VERSION "dbc-export 1 2025.20.8"

NS_ :

BS_:

BU_: ADSP APB APP APS APSB BB BMS CC CMP CMPD CP DAS DI DIF DIR DPB EPAS3P EPAS3S EPASTP EPASTS EPBL EPBR ESP EVSE FC GTW HCML HCMR HVP IBST ICR IDB LS OCS1P ODIN PARK PCS PLG PM PMF PMR PNCD PTC RADC RCM RCM2 RCM3 RCU SCCM SCM SCS SDCR TAS TCU TPMS TRCM UDS UI UIS UMC USM VC VCFRONT VCLEFT VCRIGHT VCSEC VEH

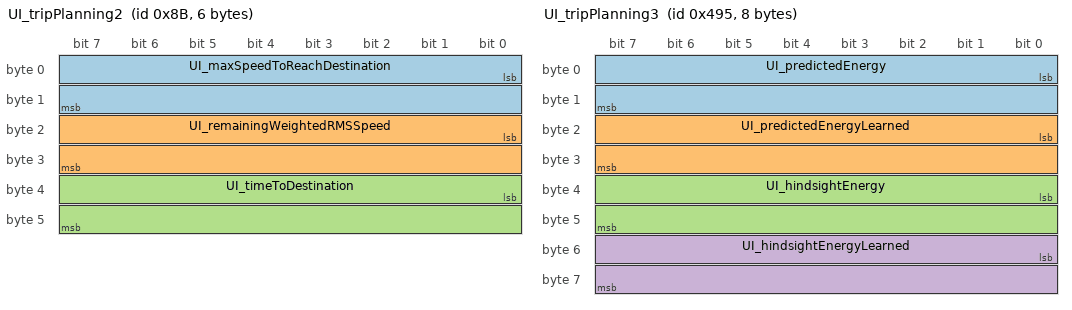
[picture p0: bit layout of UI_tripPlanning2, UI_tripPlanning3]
BO_ 139 UI_tripPlanning2: 6 UI
 SG_ UI_maxSpeedToReachDestination : 0|16@1+ (0.01,0) [0|655.34] "m/s" Vector__XXX
 SG_ UI_remainingWeightedRMSSpeed : 16|16@1+ (0.01,0) [0|655.34] "m/s" Vector__XXX
 SG_ UI_timeToDestination : 32|16@1+ (1,0) [0|65534] "s" Vector__XXX

BO_ 1173 UI_tripPlanning3: 8 UI
 SG_ UI_predictedEnergy : 0|16@1- (0.01,0) [-327.67|327.67] "kWh" Vector__XXX
 SG_ UI_predictedEnergyLearned : 16|16@1- (0.01,0) [-327.68|327.67] "kWh" Vector__XXX
 SG_ UI_hindsightEnergy : 32|16@1- (0.01,0) [-327.67|327.67] "kWh" Vector__XXX
 SG_ UI_hindsightEnergyLearned : 48|16@1- (0.01,0) [-327.68|327.67] "kWh" Vector__XXX

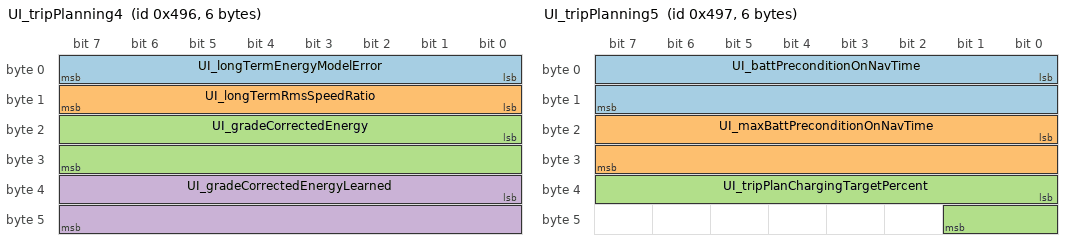
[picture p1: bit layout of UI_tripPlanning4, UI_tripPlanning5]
BO_ 1174 UI_tripPlanning4: 6 UI
 SG_ UI_longTermEnergyModelError : 0|8@1- (0.5,0) [-64|63.5] "whpm" Vector__XXX
 SG_ UI_longTermRmsSpeedRatio : 8|8@1+ (0.01,0) [0|2.54] "1" Vector__XXX
 SG_ UI_gradeCorrectedEnergy : 16|16@1- (0.01,0) [-327.68|327.67] "kWh" Vector__XXX
 SG_ UI_gradeCorrectedEnergyLearned : 32|16@1- (0.01,0) [-327.68|327.67] "kWh" Vector__XXX

BO_ 1175 UI_tripPlanning5: 6 UI
 SG_ UI_battPreconditionOnNavTime : 0|16@1+ (1,0) [0|65534] "s" Vector__XXX
 SG_ UI_maxBattPreconditionOnNavTime : 16|16@1+ (1,0) [0|65534] "s" Vector__XXX
 SG_ UI_tripPlanChargingTargetPercent : 32|10@1+ (0.1,0) [0|102.2] "%" Vector__XXX

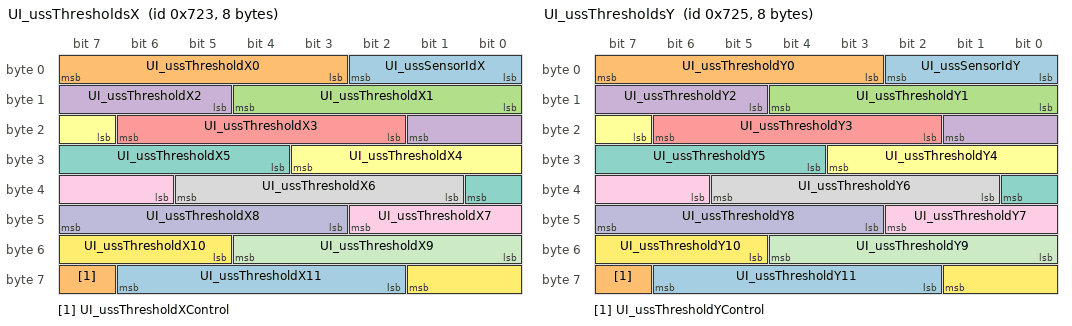
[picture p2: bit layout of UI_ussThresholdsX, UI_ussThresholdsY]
BO_ 1827 UI_ussThresholdsX: 8 UI
 SG_ UI_ussSensorIdX : 0|3@1+ (1,0) [0|7] "" Vector__XXX
 SG_ UI_ussThresholdX0 : 3|5@1+ (1,0) [0|31] "" Vector__XXX
 SG_ UI_ussThresholdX1 : 8|5@1+ (1,0) [0|31] "" Vector__XXX
 SG_ UI_ussThresholdX2 : 13|5@1+ (1,0) [0|31] "" Vector__XXX
 SG_ UI_ussThresholdX3 : 18|5@1+ (1,0) [0|31] "" Vector__XXX
 SG_ UI_ussThresholdX4 : 23|5@1+ (1,0) [0|31] "" Vector__XXX
 SG_ UI_ussThresholdX5 : 28|5@1+ (1,0) [0|31] "" Vector__XXX
 SG_ UI_ussThresholdX6 : 33|5@1+ (1,0) [0|31] "" Vector__XXX
 SG_ UI_ussThresholdX7 : 38|5@1+ (1,0) [0|31] "" Vector__XXX
 SG_ UI_ussThresholdX8 : 43|5@1+ (1,0) [0|31] "" Vector__XXX
 SG_ UI_ussThresholdX9 : 48|5@1+ (1,0) [0|31] "" Vector__XXX
 SG_ UI_ussThresholdX10 : 53|5@1+ (1,0) [0|31] "" Vector__XXX
 SG_ UI_ussThresholdX11 : 58|5@1+ (1,0) [0|31] "" Vector__XXX
 SG_ UI_ussThresholdXControl : 63|1@1+ (1,0) [0|1] "" Vector__XXX

BO_ 1829 UI_ussThresholdsY: 8 UI
 SG_ UI_ussSensorIdY : 0|3@1+ (1,0) [0|7] "" Vector__XXX
 SG_ UI_ussThresholdY0 : 3|5@1+ (1,0) [0|31] "" Vector__XXX
 SG_ UI_ussThresholdY1 : 8|5@1+ (1,0) [0|31] "" Vector__XXX
 SG_ UI_ussThresholdY2 : 13|5@1+ (1,0) [0|31] "" Vector__XXX
 SG_ UI_ussThresholdY3 : 18|5@1+ (1,0) [0|31] "" Vector__XXX
 SG_ UI_ussThresholdY4 : 23|5@1+ (1,0) [0|31] "" Vector__XXX
 SG_ UI_ussThresholdY5 : 28|5@1+ (1,0) [0|31] "" Vector__XXX
 SG_ UI_ussThresholdY6 : 33|5@1+ (1,0) [0|31] "" Vector__XXX
 SG_ UI_ussThresholdY7 : 38|5@1+ (1,0) [0|31] "" Vector__XXX
 SG_ UI_ussThresholdY8 : 43|5@1+ (1,0) [0|31] "" Vector__XXX
 SG_ UI_ussThresholdY9 : 48|5@1+ (1,0) [0|31] "" Vector__XXX
 SG_ UI_ussThresholdY10 : 53|5@1+ (1,0) [0|31] "" Vector__XXX
 SG_ UI_ussThresholdY11 : 58|5@1+ (1,0) [0|31] "" Vector__XXX
 SG_ UI_ussThresholdYControl : 63|1@1+ (1,0) [0|1] "" Vector__XXX

BO_ 627 UI_vehicleControl: 8 UI
 SG_ UI_powerStateRequest : 0|2@1+ (1,0) [0|3] "" Vector__XXX
 SG_ UI_childDoorLockOnRight : 2|1@1+ (1,0) [0|1] "" Vector__XXX
 SG_ UI_frontFogSwitch : 3|1@1+ (1,0) [0|1] "" Vector__XXX
 SG_ UI_summonActive : 4|1@1+ (1,0) [0|1] "" Vector__XXX
 SG_ UI_frunkRequest : 5|1@1+ (1,0) [0|1] "" Vector__XXX
 SG_ UI_wiperMode : 6|2@1+ (1,0) [1|3] "" Vector__XXX
 SG_ UI_steeringBacklightEnabled : 8|1@1+ (1,0) [0|1] "" Vector__XXX
 SG_ UI_steeringButtonMode : 9|3@1+ (1,0) [0|7] "" Vector__XXX
 SG_ UI_walkUpUnlock : 12|1@1+ (1,0) [0|1] "" Vector__XXX
 SG_ UI_walkAwayLock : 13|1@1+ (1,0) [0|1] "" Vector__XXX
 SG_ UI_unlockOnPark : 14|1@1+ (1,0) [0|1] "" Vector__XXX
 SG_ UI_globalUnlockOn : 15|1@1+ (1,0) [0|1] "" Vector__XXX
 SG_ UI_childDoorLockOnLeft : 16|1@1+ (1,0) [0|1] "" Vector__XXX
 SG_ UI_lockRequest : 17|3@1+ (1,0) [0|6] "" Vector__XXX
 SG_ UI_alarmEnabled : 20|1@1+ (1,0) [0|1] "" Vector__XXX
 SG_ UI_intrusionSensorOn : 21|1@1+ (1,0) [0|1] "" Vector__XXX
 SG_ UI_stop12vSupport : 22|1@1+ (1,0) [0|1] "" Vector__XXX
 SG_ UI_rearFogSwitch : 23|1@1+ (1,0) [0|1] "" Vector__XXX
 SG_ UI_mirrorFoldRequest : 24|2@1+ (1,0) [0|2] "" Vector__XXX
 SG_ UI_mirrorHeatRequest : 26|1@1+ (1,0) [0|1] "" Vector__XXX
 SG_ UI_remoteStartRequest : 27|3@1+ (1,0) [0|7] "" Vector__XXX
 SG_ UI_seeYouHomeLightingOn : 30|1@1+ (1,0) [0|1] "" Vector__XXX
 SG_ UI_powerOff : 31|1@1+ (1,0) [0|1] "" Vector__XXX
 SG_ UI_displayBrightnessLevel : 32|8@1+ (0.5,0) [0|127] "%" Vector__XXX
 SG_ UI_ambientLightingEnabled : 40|1@1+ (1,0) [0|1] "" Vector__XXX
 SG_ UI_autoHighBeamEnabled : 41|1@1+ (1,0) [0|1] "" Vector__XXX
 SG_ UI_frontLeftSeatHeatReq : 42|2@1+ (1,0) [0|3] "" Vector__XXX
 SG_ UI_frontRightSeatHeatReq : 44|2@1+ (1,0) [0|3] "" Vector__XXX
 SG_ UI_rearLeftSeatHeatReq : 46|2@1+ (1,0) [0|3] "" Vector__XXX
 SG_ UI_rearCenterSeatHeatReq : 48|2@1+ (1,0) [0|3] "" Vector__XXX
 SG_ UI_rearRightSeatHeatReq : 50|2@1+ (1,0) [0|3] "" Vector__XXX
 SG_ UI_autoFoldMirrorsOn : 52|1@1+ (1,0) [0|1] "" Vector__XXX
 SG_ UI_mirrorDipOnReverse : 53|1@1+ (1,0) [0|1] "" Vector__XXX
 SG_ UI_remoteClosureRequest : 54|2@1+ (1,0) [0|2] "" Vector__XXX
 SG_ UI_wiperRequest : 56|3@1+ (1,0) [1|7] "" Vector__XXX
 SG_ UI_domeLightSwitch : 59|2@1+ (1,0) [0|3] "" Vector__XXX
 SG_ UI_honkHorn : 61|1@1+ (1,0) [0|1] "" Vector__XXX
 SG_ UI_driveStateRequest : 62|1@1+ (1,0) [0|1] "" Vector__XXX
 SG_ UI_rearWindowLockout : 63|1@1+ (1,0) [0|1] "" Vector__XXX

BO_ 947 UI_vehicleControl2: 8 UI
 SG_ UI_gloveboxRequest : 0|1@1+ (1,0) [0|1] "" Vector__XXX
 SG_ UI_trunkRequest : 1|1@1+ (1,0) [0|1] "" Vector__XXX
 SG_ UI_UMCUpdateInhibit : 2|1@1+ (1,0) [0|1] "" Vector__XXX
 SG_ UI_WCUpdateInhibit : 3|1@1+ (1,0) [0|1] "" Vector__XXX
 SG_ UI_soundHornOnLock : 4|1@1+ (1,0) [0|1] "" Vector__XXX
 SG_ UI_locksPanelActive : 5|1@1+ (1,0) [0|1] "" Vector__XXX
 SG_ UI_PINToDriveEnabled : 6|1@1+ (1,0) [0|1] "" Vector__XXX
 SG_ UI_PINToDrivePassed : 7|1@1+ (1,0) [0|1] "" Vector__XXX
 SG_ UI_disableMirrorAutoDim : 8|1@1+ (1,0) [0|1] "" Vector__XXX
 SG_ UI_lightSwitch : 9|3@1+ (1,0) [0|7] "" Vector__XXX
 SG_ UI_readyToAddKey : 12|1@1+ (1,0) [0|1] "" Vector__XXX
 SG_ UI_alarmTriggerRequest : 13|1@1+ (1,0) [0|1] "" Vector__XXX
 SG_ UI_VCSECFeature1 : 14|1@1+ (1,0) [0|1] "" Vector__XXX
 SG_ UI_VCLEFTFeature1 : 15|1@1+ (1,0) [0|1] "" Vector__XXX
 SG_ UI_summonState : 16|2@1+ (1,0) [1|3] "" Vector__XXX
 SG_ UI_displayOnForUser : 18|1@1+ (1,0) [0|1] "" Vector__XXX
 SG_ UI_freeRollModeRequest : 19|1@1+ (1,0) [0|1] "" Vector__XXX
 SG_ UI_BLEPushNotificationRequest : 20|1@1+ (1,0) [0|1] "" Vector__XXX
 SG_ UI_pairKeyQRCodeDisplaying : 21|1@1+ (1,0) [0|1] "" Vector__XXX
 SG_ UI_keepAutopilotAwake : 22|1@1+ (1,0) [0|1] "" Vector__XXX
 SG_ UI_batteryPreconditioningRequest : 23|1@1+ (1,0) [0|1] "" Vector__XXX
 SG_ UI_coastDownMode : 24|1@1+ (1,0) [0|1] "" Vector__XXX
 SG_ UI_autopilotPowerStateRequest : 25|2@1+ (1,0) [0|3] "" Vector__XXX
 SG_ UI_shorted12VCellTestMode : 27|2@1+ (1,0) [0|3] "" Vector__XXX
 SG_ UI_autoRollWindowsOnLockEnable : 29|1@1+ (1,0) [0|1] "" Vector__XXX
 SG_ UI_virtualPitchSensorOverrideOKF : 30|1@1+ (1,0) [0|1] "" Vector__XXX
 SG_ UI_conditionalLoggingEnabledVCSE : 31|1@1+ (1,0) [0|1] "" Vector__XXX
 SG_ UI_WC3UpdateInhibit : 32|1@1+ (1,0) [0|1] "" Vector__XXX
 SG_ UI_steeringWheelHeatReq : 33|1@1+ (1,0) [0|1] "" Vector__XXX
 SG_ UI_disableHorn : 34|1@1+ (1,0) [0|1] "" Vector__XXX
 SG_ UI_frontLeftSeatFanReq : 37|2@1+ (1,0) [0|3] "" Vector__XXX
 SG_ UI_frontRightSeatAutoClimateReq : 39|1@1+ (1,0) [0|1] "" Vector__XXX
 SG_ UI_frontRightSeatFanReq : 40|2@1+ (1,0) [0|3] "" Vector__XXX
 SG_ UI_sleepFeature1 : 51|1@1+ (1,0) [0|1] "" Vector__XXX
 SG_ UI_dcr12VThreshold : 52|4@1+ (1,0) [0|15] "" Vector__XXX
 SG_ UI_frontLeftSeatAutoClimateReq : 56|1@1+ (1,0) [0|1] "" Vector__XXX
 SG_ UI_wiperHeaterReq : 57|1@1+ (1,0) [0|1] "" Vector__XXX
 SG_ UI_tireSeason : 59|1@1+ (1,0) [0|1] "" Vector__XXX
 SG_ UI_saveTireConfigReq : 60|1@1+ (1,0) [0|1] "" Vector__XXX
 SG_ UI_silentAlarm : 61|1@1+ (1,0) [0|1] "" Vector__XXX
 SG_ UI_sleepFeature2 : 63|1@1+ (1,0) [0|1] "" Vector__XXX

BO_ 628 UI_vehicleControl3: 8 UI
 SG_ UI_lightFlashRequest : 0|2@1+ (1,0) [0|3] "" Vector__XXX
 SG_ UI_keylessDrivingEnabled : 2|1@1+ (1,0) [0|1] "" Vector__XXX
 SG_ UI_phoneCallActive : 3|1@1+ (1,0) [0|1] "" Vector__XXX
 SG_ UI_drivingSideVEH : 4|2@1+ (1,0) [0|3] "" Vector__XXX
 SG_ UI_keyPairResponse : 6|2@1+ (1,0) [0|3] "" Vector__XXX
 SG_ UI_lightShowClosuresEnabled : 8|1@1+ (1,0) [0|1] "" Vector__XXX
 SG_ UI_steeringWheelHeatAutoReq : 9|1@1+ (1,0) [0|1] "" Vector__XXX
 SG_ UI_steeringWheelHeatLevelReq : 10|2@1+ (1,0) [0|3] "" Vector__XXX
 SG_ UI_headlightPulseRequest : 12|1@1+ (1,0) [0|1] "" Vector__XXX
 SG_ UI_VCSECFeature2 : 13|1@1+ (1,0) [0|1] "" Vector__XXX
 SG_ UI_VCSECFeature3 : 14|1@1+ (1,0) [0|1] "" Vector__XXX
 SG_ UI_VCSECFeature4 : 15|1@1+ (1,0) [0|1] "" Vector__XXX
 SG_ UI_VCSECFeature5 : 16|1@1+ (1,0) [0|1] "" Vector__XXX
 SG_ UI_shortHornRequest : 17|1@1+ (1,0) [0|1] "" Vector__XXX
 SG_ UI_packTempLoggingRequest : 18|1@1+ (1,0) [0|1] "" Vector__XXX
 SG_ UI_UMC3UpdateInhibit : 22|1@1+ (1,0) [0|1] "" Vector__XXX
 SG_ UI_handsFreeTrunk : 23|1@1+ (1,0) [0|1] "" Vector__XXX
 SG_ UI_displayRedShiftActive : 24|1@1+ (1,0) [0|1] "" Vector__XXX
 SG_ UI_handsFreeFrunk : 25|1@1+ (1,0) [0|1] "" Vector__XXX
 SG_ UI_fasciaCameraWashRequest : 26|1@1+ (1,0) [0|1] "" Vector__XXX
 SG_ UI_autoClosuresExcludeHome : 27|1@1+ (1,0) [0|1] "" Vector__XXX
 SG_ UI_leftRearSeatAdjustmentRequest : 28|3@1+ (1,0) [0|7] "" Vector__XXX
 SG_ UI_rightRearSeatAdjustmentReques : 32|3@1+ (1,0) [0|7] "" Vector__XXX
 SG_ UI_blindSpotIndicatorLightReques : 35|1@1+ (1,0) [0|1] "" Vector__XXX
 SG_ UI_etcBluetoothControl : 36|2@1+ (1,0) [0|3] "" Vector__XXX
 SG_ UI_keepOnAccessoryPortsReq : 38|1@1+ (1,0) [0|1] "" Vector__XXX
 SG_ UI_fasciaCameraShown : 39|1@1+ (1,0) [0|1] "" Vector__XXX
 SG_ UI_rearSeatChildLock : 40|2@1+ (1,0) [0|3] "" Vector__XXX
 SG_ UI_windowPercentageRequest : 42|6@1- (5,0) [-100|100] "%" Vector__XXX
 SG_ UI_windowRequestedFL : 48|1@1+ (1,0) [0|1] "" Vector__XXX
 SG_ UI_windowRequestedFR : 49|1@1+ (1,0) [0|1] "" Vector__XXX
 SG_ UI_windowRequestedRL : 50|1@1+ (1,0) [0|1] "" Vector__XXX
 SG_ UI_windowRequestedRR : 51|1@1+ (1,0) [0|1] "" Vector__XXX
 SG_ UI_windowRequest : 52|3@1+ (1,0) [0|7] "" Vector__XXX
 SG_ UI_closeTrunkRequest : 55|1@1+ (1,0) [0|1] "" Vector__XXX
 SG_ UI_childPresenceDetectionDisable : 56|1@1+ (1,0) [0|1] "" Vector__XXX
 SG_ UI_derivedLoadshedFeature : 59|1@1+ (1,0) [0|1] "" Vector__XXX
 SG_ UI_rearSeatFoldConfirmed : 60|1@1+ (1,0) [0|1] "" Vector__XXX
 SG_ UI_leftRearSeatRequestFromRearDi : 61|1@1+ (1,0) [0|1] "" Vector__XXX
 SG_ UI_selfParkStandingBy : 62|1@1+ (1,0) [0|1] "" Vector__XXX
 SG_ UI_rightRearSeatRequestFromRearD : 63|1@1+ (1,0) [0|1] "" Vector__XXX

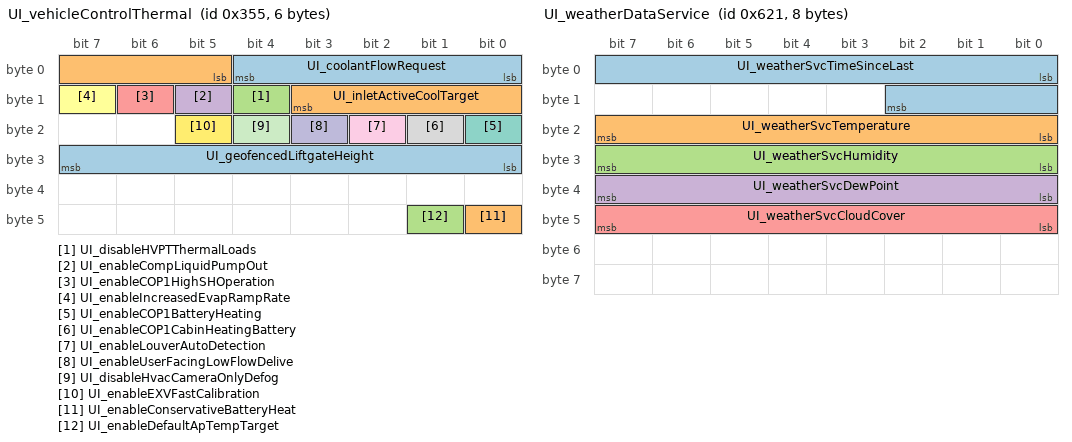
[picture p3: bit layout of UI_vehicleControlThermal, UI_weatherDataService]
BO_ 853 UI_vehicleControlThermal: 6 UI
 SG_ UI_coolantFlowRequest : 0|5@1+ (1,0) [0|25] "LPM" Vector__XXX
 SG_ UI_inletActiveCoolTarget : 5|7@1+ (1,0) [0|127] "degC" Vector__XXX
 SG_ UI_disableHVPTThermalLoads : 12|1@1+ (1,0) [0|1] "" Vector__XXX
 SG_ UI_enableCompLiquidPumpOut : 13|1@1+ (1,0) [0|1] "" Vector__XXX
 SG_ UI_enableCOP1HighSHOperation : 14|1@1+ (1,0) [0|1] "" Vector__XXX
 SG_ UI_enableIncreasedEvapRampRate : 15|1@1+ (1,0) [0|1] "" Vector__XXX
 SG_ UI_enableCOP1BatteryHeating : 16|1@1+ (1,0) [0|1] "" Vector__XXX
 SG_ UI_enableCOP1CabinHeatingBattery : 17|1@1+ (1,0) [0|1] "" Vector__XXX
 SG_ UI_enableLouverAutoDetection : 18|1@1+ (1,0) [0|1] "" Vector__XXX
 SG_ UI_enableUserFacingLowFlowDelive : 19|1@1+ (1,0) [0|1] "" Vector__XXX
 SG_ UI_disableHvacCameraOnlyDefog : 20|1@1+ (1,0) [0|1] "" Vector__XXX
 SG_ UI_enableEXVFastCalibration : 21|1@1+ (1,0) [0|1] "" Vector__XXX
 SG_ UI_geofencedLiftgateHeight : 24|8@1+ (1,0) [0|254] "cm" Vector__XXX
 SG_ UI_enableConservativeBatteryHeat : 40|1@1+ (1,0) [0|1] "" Vector__XXX
 SG_ UI_enableDefaultApTempTarget : 41|1@1+ (1,0) [0|1] "" Vector__XXX

BO_ 644 UI_vehicleModes: 8 UI
 SG_ UI_factoryMode : 0|1@1+ (1,0) [0|1] "" Vector__XXX
 SG_ UI_transportMode : 1|1@1+ (1,0) [0|1] "" Vector__XXX
 SG_ UI_showroomMode : 2|1@1+ (1,0) [0|1] "" Vector__XXX
 SG_ UI_serviceMode : 3|1@1+ (1,0) [0|1] "" Vector__XXX
 SG_ UI_isDelivered : 4|1@1+ (1,0) [0|1] "" Vector__XXX
 SG_ UI_hasEverBeenDelivered : 5|1@1+ (1,0) [0|1] "" Vector__XXX
 SG_ UI_homelinkV2Command0 : 8|8@1+ (1,0) [0|255] "" Vector__XXX
 SG_ UI_homelinkV2Command1 : 16|8@1+ (1,0) [0|255] "" Vector__XXX
 SG_ UI_homelinkV2Command2 : 24|8@1+ (1,0) [0|255] "" Vector__XXX
 SG_ UI_carWashMode : 32|1@1+ (1,0) [0|1] "" Vector__XXX
 SG_ UI_valetMode : 33|1@1+ (1,0) [0|1] "" Vector__XXX
 SG_ UI_gameMode : 34|1@1+ (1,0) [0|1] "" Vector__XXX
 SG_ UI_diagnosticsAllowed : 35|1@1+ (1,0) [0|1] "" Vector__XXX
 SG_ UI_serviceModePlus : 36|1@1+ (1,0) [0|1] "" Vector__XXX
 SG_ UI_premiumAmpPowerOff : 37|1@1+ (1,0) [0|1] "" Vector__XXX
 SG_ UI_signedCmdHardLocked : 38|1@1+ (1,0) [0|1] "" Vector__XXX
 SG_ UI_signedCmdServiceMode : 39|1@1+ (1,0) [0|1] "" Vector__XXX
 SG_ UI_closureEasterEggStatus : 40|2@1+ (1,0) [0|3] "" Vector__XXX
 SG_ UI_lightShowType : 42|3@1+ (1,0) [0|7] "" Vector__XXX
 SG_ UI_sohTestRequest : 45|1@1+ (1,0) [0|1] "" Vector__XXX
 SG_ UI_vehicleModesCounter : 52|4@1+ (1,0) [0|15] "" Vector__XXX
 SG_ UI_vehicleModesChecksum : 56|8@1+ (1,0) [0|255] "" Vector__XXX

BO_ 595 UI_ventPanelControlRequest: 8 UI
 SG_ UI_ventPanelControlRequestIndex M : 0|1@1+ (1,0) [0|1] "" Vector__XXX
 SG_ UI_ventPanelLeftPositionX m0 : 8|8@1+ (0.5,0) [0|100] "%" Vector__XXX
 SG_ UI_ventPanelLeftPositionY m0 : 16|8@1+ (0.5,0) [0|100] "%" Vector__XXX
 SG_ UI_ventPanelLeftLateralSplit m0 : 24|8@1+ (0.5,0) [0|100] "%" Vector__XXX
 SG_ UI_ventPanelRightPositionX m0 : 32|8@1+ (0.5,0) [0|100] "%" Vector__XXX
 SG_ UI_ventPanelRightPositionY m0 : 40|8@1+ (0.5,0) [0|100] "%" Vector__XXX
 SG_ UI_ventPanelRightLateralSplit m0 : 48|8@1+ (0.5,0) [0|100] "%" Vector__XXX
 SG_ UI_ventPanelLeftLateralMode m0 : 56|2@1+ (1,0) [0|3] "" Vector__XXX
 SG_ UI_ventPanelRightLateralMode m0 : 58|2@1+ (1,0) [0|3] "" Vector__XXX
 SG_ UI_hvacReqActiveVents m0 : 60|2@1+ (1,0) [0|3] "" Vector__XXX
 SG_ UI_vent2RLeftPositionX m1 : 8|8@1+ (0.5,0) [0|100] "%" Vector__XXX
 SG_ UI_vent2RLeftPositionY m1 : 16|8@1+ (0.5,0) [0|100] "%" Vector__XXX
 SG_ UI_vent2RRightPositionX m1 : 24|8@1+ (0.5,0) [0|100] "%" Vector__XXX
 SG_ UI_vent2RRightPositionY m1 : 32|8@1+ (0.5,0) [0|100] "%" Vector__XXX

BO_ 1569 UI_weatherDataService: 8 UI
 SG_ UI_weatherSvcTimeSinceLast : 0|11@1+ (1,0) [0|2046] "minutes" Vector__XXX
 SG_ UI_weatherSvcTemperature : 16|8@1- (0.5,0) [-64|63] "degC" Vector__XXX
 SG_ UI_weatherSvcHumidity : 24|8@1+ (0.5,0) [0|127] "%" Vector__XXX
 SG_ UI_weatherSvcDewPoint : 32|8@1+ (0.5,0) [0|127] "degC" Vector__XXX
 SG_ UI_weatherSvcCloudCover : 40|8@1+ (0.5,0) [0|127] "%" Vector__XXX

BO_ 1533 UMC_alertLog: 8 UMC
 SG_ UMC_alertID M : 0|15@1+ (1,0) [0|32767] "" Vector__XXX
 SG_ UMC_alertType : 15|1@1+ (1,0) [0|1] "" Vector__XXX
 SG_ UMC_a001_groundImpedance m1 : 32|32@1+ (1,0) [0|4294967295] "Ohm" Vector__XXX
 SG_ UMC_a002_ccidRmsCurrent m2 : 16|12@1+ (0.001,0) [0|4.095] "A" Vector__XXX
 SG_ UMC_a002_ccidRmsCurrentAvg m2 : 28|12@1+ (0.001,0) [0|4.095] "A" Vector__XXX
 SG_ UMC_a002_ccidFaultReason m2 : 50|4@1+ (1,0) [1|15] "" Vector__XXX
 SG_ UMC_a002_ccidFaultBucket m2 : 54|4@1+ (1,0) [0|15] "" Vector__XXX
 SG_ UMC_a003_faultType m3 : 16|8@1+ (1,0) [0|255] "" Vector__XXX
 SG_ UMC_a003_ccidSelfTestDuty m3 : 24|16@1+ (0.0001,50) [50|56.5535] "A" Vector__XXX
 SG_ UMC_a003_ccidSelfTestCurrent m3 : 40|16@1+ (0.0001,0) [0|6.5535] "A" Vector__XXX
 SG_ UMC_a004_lineVoltage m4 : 16|16@1+ (1,0) [0|65535] "Vrms" Vector__XXX
 SG_ UMC_a004_inputVoltage m4 : 32|16@1+ (0.01,0) [0|655.35] "V" Vector__XXX
 SG_ UMC_a004_inputNeutralVoltage m4 : 48|16@1+ (0.01,0) [0|655.35] "V" Vector__XXX
 SG_ UMC_a005_lineVoltage m5 : 16|16@1+ (1,0) [0|65535] "Vrms" Vector__XXX
 SG_ UMC_a005_inputVoltage m5 : 32|16@1+ (0.01,0) [0|655.35] "V" Vector__XXX
 SG_ UMC_a005_inputNeutralVoltage m5 : 48|16@1+ (0.01,0) [0|655.35] "V" Vector__XXX
 SG_ UMC_a006_outputVoltage m6 : 16|16@1+ (1,0) [0|65535] "Vrms" Vector__XXX
 SG_ UMC_a006_faultType m6 : 32|4@1+ (1,0) [0|15] "" Vector__XXX
 SG_ UMC_a006_umcReceptacleVoltage m6 : 36|12@1+ (0.1,0) [0|409.5] "V" Vector__XXX
 SG_ UMC_a006_handleVoltage m6 : 48|12@1+ (0.1,0) [0|409.5] "V" Vector__XXX
 SG_ UMC_a006_line1StuckClosed m6 : 60|1@1+ (1,0) [0|1] "" Vector__XXX
 SG_ UMC_a006_line2StuckClosed m6 : 61|1@1+ (1,0) [0|1] "" Vector__XXX
 SG_ UMC_a007_pcbaTemp m7 : 16|16@1+ (1,0) [0|65535] "degC" Vector__XXX
 SG_ UMC_a008_wallPlugTemp m8 : 16|16@1+ (1,0) [0|65535] "degC" Vector__XXX
 SG_ UMC_a008_SA_region m8 : 32|4@1+ (1,0) [0|15] "" Vector__XXX
 SG_ UMC_a008_SA_current m8 : 40|8@1+ (1,0) [0|255] "A" Vector__XXX
 SG_ UMC_a009_vehConnTemp m9 : 16|16@1+ (1,0) [0|65535] "degC" Vector__XXX
 SG_ UMC_a010_inputTerminalsTemp m10 : 16|16@1+ (1,0) [0|65535] "degC" Vector__XXX
 SG_ UMC_a012_pilotHigh m12 : 16|12@1- (0.01,0) [-20.48|20.47] "V" Vector__XXX
 SG_ UMC_a012_pilotLow m12 : 28|12@1- (0.01,0) [-20.48|20.47] "V" Vector__XXX
 SG_ UMC_a013_SA_region m13 : 16|4@1+ (1,0) [0|15] "" Vector__XXX
 SG_ UMC_a013_SA_current m13 : 24|8@1+ (1,0) [0|255] "A" Vector__XXX
 SG_ UMC_a015_SA_region m15 : 16|4@1+ (1,0) [0|15] "" Vector__XXX
 SG_ UMC_a015_SA_current m15 : 24|8@1+ (1,0) [0|255] "A" Vector__XXX
 SG_ UMC_a016_pcbaTemp m16 : 16|16@1+ (1,0) [0|65535] "degC" Vector__XXX
 SG_ UMC_a017_wallPlugTemp m17 : 16|16@1+ (1,0) [0|65535] "degC" Vector__XXX
 SG_ UMC_a017_SA_region m17 : 32|4@1+ (1,0) [0|15] "" Vector__XXX
 SG_ UMC_a017_SA_current m17 : 40|8@1+ (1,0) [0|255] "A" Vector__XXX
 SG_ UMC_a018_vehConnTemp m18 : 16|16@1+ (1,0) [0|65535] "degC" Vector__XXX
 SG_ UMC_a019_inputTerminalsTemp m19 : 16|16@1+ (1,0) [0|65535] "degC" Vector__XXX
 SG_ UMC_a024_groundImpedance m24 : 32|32@1+ (1,0) [0|4294967295] "Ohm" Vector__XXX
 SG_ UMC_a040_groundImpedance m40 : 32|32@1+ (1,0) [0|4294967295] "Ohm" Vector__XXX

BO_ 824 UMC_alertMatrix1: 8 UMC
 SG_ UMC_a001_gndMonIntrptLineSide : 0|1@1+ (1,0) [0|1] "" Vector__XXX
 SG_ UMC_a002_GFCITripped : 1|1@1+ (1,0) [0|1] "" Vector__XXX
 SG_ UMC_a003_GFCISelfTestFault : 2|1@1+ (1,0) [0|1] "" Vector__XXX
 SG_ UMC_a004_inputOverVoltage : 3|1@1+ (1,0) [0|1] "" Vector__XXX
 SG_ UMC_a005_inputUnderVoltage : 4|1@1+ (1,0) [0|1] "" Vector__XXX
 SG_ UMC_a006_contactorWelded : 5|1@1+ (1,0) [0|1] "" Vector__XXX
 SG_ UMC_a007_pcbaOT : 6|1@1+ (1,0) [0|1] "" Vector__XXX
 SG_ UMC_a008_wallPlugOT : 7|1@1+ (1,0) [0|1] "" Vector__XXX
 SG_ UMC_a009_vehConnOT : 8|1@1+ (1,0) [0|1] "" Vector__XXX
 SG_ UMC_a010_inputOT : 9|1@1+ (1,0) [0|1] "" Vector__XXX
 SG_ UMC_a011_proxDisconnected : 10|1@1+ (1,0) [0|1] "" Vector__XXX
 SG_ UMC_a012_pilotFault : 11|1@1+ (1,0) [0|1] "" Vector__XXX
 SG_ UMC_a013_SA_Temperature : 12|1@1+ (1,0) [0|1] "" Vector__XXX
 SG_ UMC_a014_SA_Genealogy : 13|1@1+ (1,0) [0|1] "" Vector__XXX
 SG_ UMC_a015_SA_Connection : 14|1@1+ (1,0) [0|1] "" Vector__XXX
 SG_ UMC_a016_pcbaOTFoldback : 15|1@1+ (1,0) [0|1] "" Vector__XXX
 SG_ UMC_a017_wallPlugOTFoldback : 16|1@1+ (1,0) [0|1] "" Vector__XXX
 SG_ UMC_a018_vehConnOTFoldback : 17|1@1+ (1,0) [0|1] "" Vector__XXX
 SG_ UMC_a019_inputOTFoldback : 18|1@1+ (1,0) [0|1] "" Vector__XXX
 SG_ UMC_a020_applicationCRC : 19|1@1+ (1,0) [0|1] "" Vector__XXX
 SG_ UMC_a021_dataBus : 20|1@1+ (1,0) [0|1] "" Vector__XXX
 SG_ UMC_a022_criticalRAM : 21|1@1+ (1,0) [0|1] "" Vector__XXX
 SG_ UMC_a023_adcSelfTest : 22|1@1+ (1,0) [0|1] "" Vector__XXX
 SG_ UMC_a024_gndResistanceHigh : 23|1@1+ (1,0) [0|1] "" Vector__XXX
 SG_ UMC_a025_cntrOpenExpectedClose : 24|1@1+ (1,0) [0|1] "" Vector__XXX
 SG_ UMC_a026_vRefOutOfRange : 25|1@1+ (1,0) [0|1] "" Vector__XXX
 SG_ UMC_a027_watchdogExpired : 26|1@1+ (1,0) [0|1] "" Vector__XXX
 SG_ UMC_a028_processorBooted : 27|1@1+ (1,0) [0|1] "" Vector__XXX
 SG_ UMC_a029_acPowerLoss : 28|1@1+ (1,0) [0|1] "" Vector__XXX
 SG_ UMC_a030_acLostPllLock : 29|1@1+ (1,0) [0|1] "" Vector__XXX
 SG_ UMC_a031_relayCoilVIrrational : 30|1@1+ (1,0) [0|1] "" Vector__XXX
 SG_ UMC_a032_chcVitalsRequestFailure : 31|1@1+ (1,0) [0|1] "" Vector__XXX
 SG_ UMC_a033_chcUpdateFault : 32|1@1+ (1,0) [0|1] "" Vector__XXX
 SG_ UMC_a034_v2lSAUnsupported : 33|1@1+ (1,0) [0|1] "" Vector__XXX
 SG_ UMC_a035_v2lHVACDetected : 34|1@1+ (1,0) [0|1] "" Vector__XXX
 SG_ UMC_a037_GFCICalibration : 36|1@1+ (1,0) [0|1] "" Vector__XXX
 SG_ UMC_a038_chcVitalsFault : 37|1@1+ (1,0) [0|1] "" Vector__XXX
 SG_ UMC_a039_inputOverCurrent : 38|1@1+ (1,0) [0|1] "" Vector__XXX
 SG_ UMC_a040_gndDisconnected : 39|1@1+ (1,0) [0|1] "" Vector__XXX

BO_ 1285 UMC_smartAdapterInfo: 8 UMC
 SG_ SA_infoIndex M : 0|8@1+ (1,0) [0|255] "" Vector__XXX
 SG_ SA_genealogyVersion m0 : 8|8@1+ (1,0) [0|255] "" Vector__XXX
 SG_ SA_genealogyCrc m0 : 16|32@1+ (1,0) [0|4294967295] "" Vector__XXX
 SG_ SA_region m0 : 48|4@1+ (1,0) [0|15] "" Vector__XXX
 SG_ SA_OverTempThreshold m0 : 56|8@1+ (1,0) [0|255] "" Vector__XXX
 SG_ SA_partNumInt m31 : 8|32@1+ (1,0) [0|4294967295] "" Vector__XXX
 SG_ SA_partNumRev m31 : 40|8@1+ (1,0) [0|255] "" Vector__XXX
 SG_ SA_currentLimit m31 : 48|8@1+ (1,0) [0|255] "" Vector__XXX
 SG_ SA_l1Voltage m31 : 56|8@1+ (1,0) [0|255] "" Vector__XXX

BO_TX_BU_ 139 : UI;
BO_TX_BU_ 1173 : UI;
BO_TX_BU_ 1174 : UI;
BO_TX_BU_ 1175 : UI;
BO_TX_BU_ 1827 : UI;
BO_TX_BU_ 1829 : UI;
BO_TX_BU_ 627 : UI;
BO_TX_BU_ 947 : UI;
BO_TX_BU_ 628 : UI;
BO_TX_BU_ 853 : UI;
BO_TX_BU_ 644 : UI;
BO_TX_BU_ 595 : UI;
BO_TX_BU_ 1569 : UI;
BO_TX_BU_ 1533 : UMC;
BO_TX_BU_ 824 : UMC;
BO_TX_BU_ 1285 : UMC;
CM_ BO_ 139 "Touchscreen user interface computer message: trip planning2";
CM_ SG_ 139 UI_maxSpeedToReachDestination "maximum speed to reach destination without significant risk of running out of energy; raw 65535 = signal not available (SNA)";
CM_ SG_ 139 UI_remainingWeightedRMSSpeed "Touchscreen user interface computer: remaining weighted RMS speed; raw 65535 = signal not available (SNA)";
CM_ SG_ 139 UI_timeToDestination "remaining time to reach destination; raw 65535 = signal not available (SNA)";
CM_ BO_ 1173 "Touchscreen user interface computer message: trip planning3";
CM_ SG_ 1173 UI_predictedEnergy "initially predicted energy in kWh for current location along navigation route; raw 32768 = signal not available (SNA)";
CM_ SG_ 1173 UI_predictedEnergyLearned "Touchscreen user interface computer: predicted energy learned; raw 32768 = signal not available (SNA)";
CM_ SG_ 1173 UI_hindsightEnergy "hindsight energy, the model predicted energy based on measured speed and acceleration for the current location along navigation route; raw 32768 = signal not available (SNA)";
CM_ SG_ 1173 UI_hindsightEnergyLearned "Touchscreen user interface computer: hindsight energy learned; raw 32768 = signal not available (SNA)";
CM_ BO_ 1174 "Touchscreen user interface computer message: trip planning4";
CM_ SG_ 1174 UI_longTermEnergyModelError "Touchscreen user interface computer: long term energy model error; raw 128 = signal not available (SNA)";
CM_ SG_ 1174 UI_longTermRmsSpeedRatio "Touchscreen user interface computer: long term rms speed ratio; raw 255 = signal not available (SNA)";
CM_ SG_ 1174 UI_gradeCorrectedEnergy "Touchscreen user interface computer: grade corrected energy; raw 32768 = signal not available (SNA)";
CM_ SG_ 1174 UI_gradeCorrectedEnergyLearned "Touchscreen user interface computer: grade corrected energy learned; raw 32768 = signal not available (SNA)";
CM_ BO_ 1175 "Touchscreen user interface computer message: trip planning5";
CM_ SG_ 1175 UI_battPreconditionOnNavTime "Touchscreen user interface computer: batt precondition on nav time; raw 65535 = signal not available (SNA)";
CM_ SG_ 1175 UI_maxBattPreconditionOnNavTime "Touchscreen user interface computer: max batt precondition on nav time; raw 65535 = signal not available (SNA)";
CM_ SG_ 1175 UI_tripPlanChargingTargetPercent "Touchscreen user interface computer: trip plan charging target percent; raw 1023 = signal not available (SNA)";
CM_ BO_ 1827 "Touchscreen user interface computer message: uss thresholds x";
CM_ SG_ 1827 UI_ussSensorIdX "Touchscreen user interface computer: uss sensor id x";
CM_ SG_ 1827 UI_ussThresholdX0 "Touchscreen user interface computer: uss threshold X0";
CM_ SG_ 1827 UI_ussThresholdX1 "Touchscreen user interface computer: uss threshold X1";
CM_ SG_ 1827 UI_ussThresholdX2 "Touchscreen user interface computer: uss threshold X2";
CM_ SG_ 1827 UI_ussThresholdX3 "Touchscreen user interface computer: uss threshold X3";
CM_ SG_ 1827 UI_ussThresholdX4 "Touchscreen user interface computer: uss threshold X4";
CM_ SG_ 1827 UI_ussThresholdX5 "Touchscreen user interface computer: uss threshold X5";
CM_ SG_ 1827 UI_ussThresholdX6 "Touchscreen user interface computer: uss threshold X6";
CM_ SG_ 1827 UI_ussThresholdX7 "Touchscreen user interface computer: uss threshold X7";
CM_ SG_ 1827 UI_ussThresholdX8 "Touchscreen user interface computer: uss threshold X8";
CM_ SG_ 1827 UI_ussThresholdX9 "Touchscreen user interface computer: uss threshold X9";
CM_ SG_ 1827 UI_ussThresholdX10 "Touchscreen user interface computer: uss threshold X10";
CM_ SG_ 1827 UI_ussThresholdX11 "Touchscreen user interface computer: uss threshold X11";
CM_ SG_ 1827 UI_ussThresholdXControl "Touchscreen user interface computer: uss threshold x control";
CM_ BO_ 1829 "Touchscreen user interface computer message: uss thresholds y";
CM_ SG_ 1829 UI_ussSensorIdY "Touchscreen user interface computer: uss sensor id y";
CM_ SG_ 1829 UI_ussThresholdY0 "Touchscreen user interface computer: uss threshold Y0";
CM_ SG_ 1829 UI_ussThresholdY1 "Touchscreen user interface computer: uss threshold Y1";
CM_ SG_ 1829 UI_ussThresholdY2 "Touchscreen user interface computer: uss threshold Y2";
CM_ SG_ 1829 UI_ussThresholdY3 "Touchscreen user interface computer: uss threshold Y3";
CM_ SG_ 1829 UI_ussThresholdY4 "Touchscreen user interface computer: uss threshold Y4";
CM_ SG_ 1829 UI_ussThresholdY5 "Touchscreen user interface computer: uss threshold Y5";
CM_ SG_ 1829 UI_ussThresholdY6 "Touchscreen user interface computer: uss threshold Y6";
CM_ SG_ 1829 UI_ussThresholdY7 "Touchscreen user interface computer: uss threshold Y7";
CM_ SG_ 1829 UI_ussThresholdY8 "Touchscreen user interface computer: uss threshold Y8";
CM_ SG_ 1829 UI_ussThresholdY9 "Touchscreen user interface computer: uss threshold Y9";
CM_ SG_ 1829 UI_ussThresholdY10 "Touchscreen user interface computer: uss threshold Y10";
CM_ SG_ 1829 UI_ussThresholdY11 "Touchscreen user interface computer: uss threshold Y11";
CM_ SG_ 1829 UI_ussThresholdYControl "Touchscreen user interface computer: uss threshold y control";
CM_ BO_ 627 "Touchscreen user interface computer message: vehicle control";
CM_ SG_ 627 UI_powerStateRequest "Request accessory power";
CM_ SG_ 627 UI_childDoorLockOnRight "UI child door lock request status.";
CM_ SG_ 627 UI_frontFogSwitch "Request for front fog lights to be on";
CM_ SG_ 627 UI_summonActive "Summon is active";
CM_ SG_ 627 UI_frunkRequest "Request open frunk";
CM_ SG_ 627 UI_wiperMode "Wiper mode state; raw 0 = signal not available (SNA)";
CM_ SG_ 627 UI_steeringBacklightEnabled "Touchscreen user interface computer: steering backlight enabled";
CM_ SG_ 627 UI_steeringButtonMode "Steering wheel control mode";
CM_ SG_ 627 UI_walkUpUnlock "Walk up unlock request (datavalue defaults to false)";
CM_ SG_ 627 UI_walkAwayLock "Walk away door lock setting.";
CM_ SG_ 627 UI_unlockOnPark "Unlock on park setting";
CM_ SG_ 627 UI_globalUnlockOn "Global Unlock Setting";
CM_ SG_ 627 UI_childDoorLockOnLeft "UI child door lock request status.";
CM_ SG_ 627 UI_lockRequest "Lock or unlock request; raw 7 = signal not available (SNA)";
CM_ SG_ 627 UI_alarmEnabled "UI customer level request to enable alarm.";
CM_ SG_ 627 UI_intrusionSensorOn "Touchscreen user interface computer: intrusion sensor on";
CM_ SG_ 627 UI_stop12vSupport "UI request to stop rails as 12v support";
CM_ SG_ 627 UI_rearFogSwitch "Request for rear fog lights to be on";
CM_ SG_ 627 UI_mirrorFoldRequest "Fold the mirrors; raw 3 = signal not available (SNA)";
CM_ SG_ 627 UI_mirrorHeatRequest "Customer usage of mirror heater and rear defrost";
CM_ SG_ 627 UI_remoteStartRequest "remote start or self park request; raw 4 = signal not available (SNA)";
CM_ SG_ 627 UI_seeYouHomeLightingOn "Headlights after exit";
CM_ SG_ 627 UI_powerOff "power off rails request.";
CM_ SG_ 627 UI_displayBrightnessLevel "UI brightness; raw 255 = signal not available (SNA)";
CM_ SG_ 627 UI_ambientLightingEnabled "Touchscreen user interface computer: ambient lighting enabled";
CM_ SG_ 627 UI_autoHighBeamEnabled "Enable Automatic High/Low Beams";
CM_ SG_ 627 UI_frontLeftSeatHeatReq "Request for front left seat heat";
CM_ SG_ 627 UI_frontRightSeatHeatReq "Request for front left seat heat";
CM_ SG_ 627 UI_rearLeftSeatHeatReq "UI request for second row left seat heater";
CM_ SG_ 627 UI_rearCenterSeatHeatReq "UI request for second row middle seat heater";
CM_ SG_ 627 UI_rearRightSeatHeatReq "UI request for second row right seat heater";
CM_ SG_ 627 UI_autoFoldMirrorsOn "Enable Automatic Mirror Fold/Unfold";
CM_ SG_ 627 UI_mirrorDipOnReverse "Enable Mirror Dip On Reverse";
CM_ SG_ 627 UI_remoteClosureRequest "remote actuate trunk; raw 3 = signal not available (SNA)";
CM_ SG_ 627 UI_wiperRequest "Wiper speed; raw 0 = signal not available (SNA)";
CM_ SG_ 627 UI_domeLightSwitch "Dome light switch";
CM_ SG_ 627 UI_honkHorn "Touchscreen user interface computer: honk horn";
CM_ SG_ 627 UI_driveStateRequest "Touchscreen user interface computer: drive state request";
CM_ SG_ 627 UI_rearWindowLockout "Touchscreen user interface computer: rear window lockout";
CM_ BO_ 947 "Touchscreen user interface computer message: vehicle control2";
CM_ SG_ 947 UI_gloveboxRequest "UI request to open the glovebox";
CM_ SG_ 947 UI_trunkRequest "Rear trunk request";
CM_ SG_ 947 UI_UMCUpdateInhibit "Touchscreen user interface computer: UMC update inhibit";
CM_ SG_ 947 UI_WCUpdateInhibit "Touchscreen user interface computer: WC update inhibit";
CM_ SG_ 947 UI_soundHornOnLock "Touchscreen user interface computer: sound horn on lock";
CM_ SG_ 947 UI_locksPanelActive "Touchscreen user interface computer: locks panel active";
CM_ SG_ 947 UI_PINToDriveEnabled "UI customer level request to pin to drive enabled.";
CM_ SG_ 947 UI_PINToDrivePassed "UI customer level request to enable drive with pin passed.";
CM_ SG_ 947 UI_disableMirrorAutoDim "Request to disable side and rear-view mirror auto dim";
CM_ SG_ 947 UI_lightSwitch "Headlight mode; raw 4 = signal not available (SNA)";
CM_ SG_ 947 UI_readyToAddKey "Ready to add key";
CM_ SG_ 947 UI_alarmTriggerRequest "Alarm activation request from UI";
CM_ SG_ 947 UI_VCSECFeature1 "Touchscreen user interface computer: VCSEC feature1";
CM_ SG_ 947 UI_VCLEFTFeature1 "Touchscreen user interface computer: VCLEFT feature1";
CM_ SG_ 947 UI_summonState "Touchscreen user interface computer: summon state; raw 0 = signal not available (SNA)";
CM_ SG_ 947 UI_displayOnForUser "User is present";
CM_ SG_ 947 UI_freeRollModeRequest "Touchscreen user interface computer: free roll mode request";
CM_ SG_ 947 UI_BLEPushNotificationRequest "Reports that the User Interface (UI) wants to talk to a phone and Vehicle Controller Security (VCSEC) should let all connected phones know.";
CM_ SG_ 947 UI_pairKeyQRCodeDisplaying "Touchscreen user interface computer: pair key QR code displaying";
CM_ SG_ 947 UI_keepAutopilotAwake "Reports the request for Vehicle Controller (VC) to keep autopilot awake.";
CM_ SG_ 947 UI_batteryPreconditioningRequest "Requests battery preconditioning.";
CM_ SG_ 947 UI_coastDownMode "Touchscreen user interface computer: coast down mode";
CM_ SG_ 947 UI_autopilotPowerStateRequest "Requests different power states from autopilot ECU depending on feature usage.";
CM_ SG_ 947 UI_shorted12VCellTestMode "Touchscreen user interface computer: shorted12 v cell test mode";
CM_ SG_ 947 UI_autoRollWindowsOnLockEnable "UI customer level request to enable auto-roll windows on lock";
CM_ SG_ 947 UI_virtualPitchSensorOverrideOKF "Touchscreen user interface computer: virtual pitch sensor override OK for aim";
CM_ SG_ 947 UI_conditionalLoggingEnabledVCSE "Touchscreen user interface computer: conditional logging enabled VCSEC";
CM_ SG_ 947 UI_WC3UpdateInhibit "Touchscreen user interface computer: WC3 update inhibit";
CM_ SG_ 947 UI_steeringWheelHeatReq "Request to enable steering wheel heater";
CM_ SG_ 947 UI_disableHorn "Request to disable horn";
CM_ SG_ 947 UI_frontLeftSeatFanReq "Request for front left seat ventilation";
CM_ SG_ 947 UI_frontRightSeatAutoClimateReq "UI setting to enable auto seat heating and cooling for front right seat";
CM_ SG_ 947 UI_frontRightSeatFanReq "Request for front left seat ventilation";
CM_ SG_ 947 UI_sleepFeature1 "Touchscreen user interface computer: sleep feature1";
CM_ SG_ 947 UI_dcr12VThreshold "Touchscreen user interface computer: dcr12 v threshold";
CM_ SG_ 947 UI_frontLeftSeatAutoClimateReq "UI setting to enable auto seat heating and cooling for front left seat";
CM_ SG_ 947 UI_wiperHeaterReq "UI request to enable the wiper heater";
CM_ SG_ 947 UI_tireSeason "Touchscreen user interface computer: tire season";
CM_ SG_ 947 UI_saveTireConfigReq "Touchscreen user interface computer: save tire config req";
CM_ SG_ 947 UI_silentAlarm "Signal indicating alarms should be silenced";
CM_ SG_ 947 UI_sleepFeature2 "Touchscreen user interface computer: sleep feature2";
CM_ BO_ 628 "Touchscreen user interface computer message: vehicle control3";
CM_ SG_ 628 UI_lightFlashRequest "UI flash lights request";
CM_ SG_ 628 UI_keylessDrivingEnabled "Touchscreen user interface computer: keyless driving enabled";
CM_ SG_ 628 UI_phoneCallActive "On phone call via Bluetooth if active";
CM_ SG_ 628 UI_drivingSideVEH "Touchscreen user interface computer: driving side VEH";
CM_ SG_ 628 UI_keyPairResponse "Touchscreen user interface computer: key pair response";
CM_ SG_ 628 UI_lightShowClosuresEnabled "Closure movements enabled during light show";
CM_ SG_ 628 UI_steeringWheelHeatAutoReq "UI setting to request auto steering wheel heat";
CM_ SG_ 628 UI_steeringWheelHeatLevelReq "Request for steering wheel heat";
CM_ SG_ 628 UI_headlightPulseRequest "Request headlights to pulse";
CM_ SG_ 628 UI_VCSECFeature2 "Touchscreen user interface computer: VCSEC feature2";
CM_ SG_ 628 UI_VCSECFeature3 "Touchscreen user interface computer: VCSEC feature3";
CM_ SG_ 628 UI_VCSECFeature4 "Touchscreen user interface computer: VCSEC feature4";
CM_ SG_ 628 UI_VCSECFeature5 "Touchscreen user interface computer: VCSEC feature5";
CM_ SG_ 628 UI_shortHornRequest "Touchscreen user interface computer: short horn request";
CM_ SG_ 628 UI_packTempLoggingRequest "Touchscreen user interface computer: pack temp logging request";
CM_ SG_ 628 UI_UMC3UpdateInhibit "Touchscreen user interface computer: UMC3 update inhibit";
CM_ SG_ 628 UI_handsFreeTrunk "Touchscreen user interface computer: hands free trunk";
CM_ SG_ 628 UI_displayRedShiftActive "UI's reduce blue light setting is active";
CM_ SG_ 628 UI_handsFreeFrunk "Touchscreen user interface computer: hands free frunk";
CM_ SG_ 628 UI_fasciaCameraWashRequest "User request to activate fascia camera wash";
CM_ SG_ 628 UI_autoClosuresExcludeHome "Touchscreen user interface computer: auto closures exclude home";
CM_ SG_ 628 UI_leftRearSeatAdjustmentRequest "Reports request from UI to actuate the left rear seat";
CM_ SG_ 628 UI_rightRearSeatAdjustmentReques "Reports request from UI to actuate the right rear seat";
CM_ SG_ 628 UI_blindSpotIndicatorLightReques "Request for blind spot indicator light";
CM_ SG_ 628 UI_etcBluetoothControl "Touchscreen user interface computer: etc bluetooth control";
CM_ SG_ 628 UI_keepOnAccessoryPortsReq "User setting to keep 12V outlets, USB ports, and phone chargers powered in CONDITIONING";
CM_ SG_ 628 UI_fasciaCameraShown "Whether the UI is currently showing the fascia camera view";
CM_ SG_ 628 UI_rearSeatChildLock "Reports the state of second row seat fold flat child lock from the UI";
CM_ SG_ 628 UI_windowPercentageRequest "Reports the window percentage value when window request is WINDOW_REQUEST_GOTO_PERCENT.";
CM_ SG_ 628 UI_windowRequestedFL "Reports that the front left window is requested.";
CM_ SG_ 628 UI_windowRequestedFR "Reports that the front right window is requested.";
CM_ SG_ 628 UI_windowRequestedRL "Reports that the rear left window is requested.";
CM_ SG_ 628 UI_windowRequestedRR "Reports that the rear right window is requested.";
CM_ SG_ 628 UI_windowRequest "Window operation request from the mobile app.";
CM_ SG_ 628 UI_closeTrunkRequest "Explicity request for the rear trunk to close";
CM_ SG_ 628 UI_childPresenceDetectionDisable "User request to disable child presence detection behaviors until the next drive cycle";
CM_ SG_ 628 UI_derivedLoadshedFeature "Reports whether vehicle controllers should enable derived loadshed feature.";
CM_ SG_ 628 UI_rearSeatFoldConfirmed "Touchscreen user interface computer: rear seat fold confirmed";
CM_ SG_ 628 UI_leftRearSeatRequestFromRearDi "Touchscreen user interface computer: left rear seat request from rear display";
CM_ SG_ 628 UI_selfParkStandingBy "Reports that summon is in standby.";
CM_ SG_ 628 UI_rightRearSeatRequestFromRearD "Touchscreen user interface computer: right rear seat request from rear display";
CM_ BO_ 853 "Touchscreen user interface computer message: vehicle control thermal";
CM_ SG_ 853 UI_coolantFlowRequest "request for coolant flow to MCU in LPM";
CM_ SG_ 853 UI_inletActiveCoolTarget "request for coolant temperature at Car Computer inlet";
CM_ SG_ 853 UI_disableHVPTThermalLoads "Request thermal system to disable active battery heating";
CM_ SG_ 853 UI_enableCompLiquidPumpOut "Touchscreen user interface computer: enable comp liquid pump out";
CM_ SG_ 853 UI_enableCOP1HighSHOperation "Touchscreen user interface computer: enable COP1 high SH operation";
CM_ SG_ 853 UI_enableIncreasedEvapRampRate "Touchscreen user interface computer: enable increased evap ramp rate";
CM_ SG_ 853 UI_enableCOP1BatteryHeating "Touchscreen user interface computer: enable COP1 battery heating";
CM_ SG_ 853 UI_enableCOP1CabinHeatingBattery "Touchscreen user interface computer: enable COP1 cabin heating battery heating";
CM_ SG_ 853 UI_enableLouverAutoDetection "Touchscreen user interface computer: enable louver auto detection";
CM_ SG_ 853 UI_enableUserFacingLowFlowDelive "Touchscreen user interface computer: enable user facing low flow delivery alert";
CM_ SG_ 853 UI_disableHvacCameraOnlyDefog "Touchscreen user interface computer: disable hvac camera only defog";
CM_ SG_ 853 UI_enableEXVFastCalibration "Touchscreen user interface computer: enable EXV fast calibration";
CM_ SG_ 853 UI_geofencedLiftgateHeight "Touchscreen user interface computer: geofenced liftgate height; raw 255 = signal not available (SNA)";
CM_ SG_ 853 UI_enableConservativeBatteryHeat "Touchscreen user interface computer: enable conservative battery heating";
CM_ SG_ 853 UI_enableDefaultApTempTarget "Touchscreen user interface computer: enable default ap temp target";
CM_ BO_ 644 "Touchscreen user interface computer message: vehicle modes";
CM_ SG_ 644 UI_factoryMode "Touchscreen user interface computer: factory mode";
CM_ SG_ 644 UI_transportMode "Reports UI Transport mode. Distinct from GTW transport mode.";
CM_ SG_ 644 UI_showroomMode "Reports UI showroom mode.";
CM_ SG_ 644 UI_serviceMode "Service diagnostics mode active";
CM_ SG_ 644 UI_isDelivered "Touchscreen user interface computer: is delivered";
CM_ SG_ 644 UI_hasEverBeenDelivered "Touchscreen user interface computer: has ever been delivered";
CM_ SG_ 644 UI_homelinkV2Command0 "Touchscreen user interface computer: homelink V2 command0";
CM_ SG_ 644 UI_homelinkV2Command1 "Touchscreen user interface computer: homelink V2 command1";
CM_ SG_ 644 UI_homelinkV2Command2 "Touchscreen user interface computer: homelink V2 command2";
CM_ SG_ 644 UI_carWashMode "Car Wash Mode";
CM_ SG_ 644 UI_valetMode "Touchscreen user interface computer: valet mode";
CM_ SG_ 644 UI_gameMode "Game mode";
CM_ SG_ 644 UI_diagnosticsAllowed "Touchscreen user interface computer: diagnostics allowed";
CM_ SG_ 644 UI_serviceModePlus "Extended service diagnostics mode active";
CM_ SG_ 644 UI_premiumAmpPowerOff "Premium amplifier power off request";
CM_ SG_ 644 UI_signedCmdHardLocked "Touchscreen user interface computer: signed cmd hard locked";
CM_ SG_ 644 UI_signedCmdServiceMode "Signal reported by Touchscreen user interface computer";
CM_ SG_ 644 UI_closureEasterEggStatus "Touchscreen user interface computer: closure easter egg status";
CM_ SG_ 644 UI_lightShowType "Type of the light show to be run";
CM_ SG_ 644 UI_sohTestRequest "Touchscreen user interface computer: soh test request";
CM_ SG_ 644 UI_vehicleModesCounter "Touchscreen user interface computer: vehicle modes counter";
CM_ SG_ 644 UI_vehicleModesChecksum "Touchscreen user interface computer: vehicle modes checksum";
CM_ BO_ 595 "Touchscreen user interface computer message: vent panel control request";
CM_ SG_ 595 UI_ventPanelControlRequestIndex "Touchscreen user interface computer: vent panel control request index";
CM_ SG_ 595 UI_ventPanelLeftPositionX "Airwave left X position.";
CM_ SG_ 595 UI_ventPanelLeftPositionY "Airwave left Y position.";
CM_ SG_ 595 UI_ventPanelLeftLateralSplit "Airwave left split amount.";
CM_ SG_ 595 UI_ventPanelRightPositionX "Airwave right X position.";
CM_ SG_ 595 UI_ventPanelRightPositionY "Airwave right Y position.";
CM_ SG_ 595 UI_ventPanelRightLateralSplit "Airwave right split amount.";
CM_ SG_ 595 UI_ventPanelLeftLateralMode "Airwave left focus or split.";
CM_ SG_ 595 UI_ventPanelRightLateralMode "Airwave right focus or split.";
CM_ SG_ 595 UI_hvacReqActiveVents "Active airwave sides - left/right/both";
CM_ SG_ 595 UI_vent2RLeftPositionX "Airwave left X position.";
CM_ SG_ 595 UI_vent2RLeftPositionY "Airwave left Y position.";
CM_ SG_ 595 UI_vent2RRightPositionX "Airwave left X position.";
CM_ SG_ 595 UI_vent2RRightPositionY "Airwave left Y position.";
CM_ BO_ 1569 "Touchscreen user interface computer message: weather data service";
CM_ SG_ 1569 UI_weatherSvcTimeSinceLast "Touchscreen user interface computer: weather svc time since last; raw 2047 = signal not available (SNA)";
CM_ SG_ 1569 UI_weatherSvcTemperature "Touchscreen user interface computer: weather svc temperature; raw 127 = signal not available (SNA)";
CM_ SG_ 1569 UI_weatherSvcHumidity "Touchscreen user interface computer: weather svc humidity; raw 255 = signal not available (SNA)";
CM_ SG_ 1569 UI_weatherSvcDewPoint "Touchscreen user interface computer: weather svc dew point; raw 255 = signal not available (SNA)";
CM_ SG_ 1569 UI_weatherSvcCloudCover "Touchscreen user interface computer: weather svc cloud cover; raw 255 = signal not available (SNA)";
CM_ BO_ 1533 "UMC ECU message: alert log";
CM_ SG_ 1533 UMC_alertID "UMC ECU: alert ID";
CM_ SG_ 1533 UMC_alertType "UMC ECU: alert type";
CM_ SG_ 1533 UMC_a001_groundImpedance "UMC ECU: a001 ground impedance";
CM_ SG_ 1533 UMC_a002_ccidRmsCurrent "UMC ECU: a002 ccid rms current";
CM_ SG_ 1533 UMC_a002_ccidRmsCurrentAvg "UMC ECU: a002 ccid rms current avg";
CM_ SG_ 1533 UMC_a002_ccidFaultReason "UMC ECU: a002 ccid fault reason; raw 0 = signal not available (SNA)";
CM_ SG_ 1533 UMC_a002_ccidFaultBucket "UMC ECU: a002 ccid fault bucket";
CM_ SG_ 1533 UMC_a003_faultType "UMC ECU: a003 fault type";
CM_ SG_ 1533 UMC_a003_ccidSelfTestDuty "UMC ECU: a003 ccid self test duty";
CM_ SG_ 1533 UMC_a003_ccidSelfTestCurrent "UMC ECU: a003 ccid self test current";
CM_ SG_ 1533 UMC_a004_lineVoltage "UMC ECU: a004 line voltage";
CM_ SG_ 1533 UMC_a004_inputVoltage "UMC ECU: a004 input voltage";
CM_ SG_ 1533 UMC_a004_inputNeutralVoltage "UMC ECU: a004 input neutral voltage";
CM_ SG_ 1533 UMC_a005_lineVoltage "UMC ECU: a005 line voltage";
CM_ SG_ 1533 UMC_a005_inputVoltage "UMC ECU: a005 input voltage";
CM_ SG_ 1533 UMC_a005_inputNeutralVoltage "UMC ECU: a005 input neutral voltage";
CM_ SG_ 1533 UMC_a006_outputVoltage "UMC ECU: a006 output voltage";
CM_ SG_ 1533 UMC_a006_faultType "UMC ECU: a006 fault type";
CM_ SG_ 1533 UMC_a006_umcReceptacleVoltage "UMC ECU: a006 umc receptacle voltage";
CM_ SG_ 1533 UMC_a006_handleVoltage "UMC ECU: a006 handle voltage";
CM_ SG_ 1533 UMC_a006_line1StuckClosed "UMC ECU: a006 line1 stuck closed";
CM_ SG_ 1533 UMC_a006_line2StuckClosed "UMC ECU: a006 line2 stuck closed";
CM_ SG_ 1533 UMC_a007_pcbaTemp "UMC ECU: a007 pcba temp";
CM_ SG_ 1533 UMC_a008_wallPlugTemp "UMC ECU: a008 wall plug temp";
CM_ SG_ 1533 UMC_a008_SA_region "UMC ECU: a008 SA region";
CM_ SG_ 1533 UMC_a008_SA_current "UMC ECU: a008 SA current";
CM_ SG_ 1533 UMC_a009_vehConnTemp "UMC ECU: a009 veh conn temp";
CM_ SG_ 1533 UMC_a010_inputTerminalsTemp "UMC ECU: a010 input terminals temp";
CM_ SG_ 1533 UMC_a012_pilotHigh "UMC ECU: a012 pilot high";
CM_ SG_ 1533 UMC_a012_pilotLow "UMC ECU: a012 pilot low";
CM_ SG_ 1533 UMC_a013_SA_region "UMC ECU: a013 SA region";
CM_ SG_ 1533 UMC_a013_SA_current "UMC ECU: a013 SA current";
CM_ SG_ 1533 UMC_a015_SA_region "UMC ECU: a015 SA region";
CM_ SG_ 1533 UMC_a015_SA_current "UMC ECU: a015 SA current";
CM_ SG_ 1533 UMC_a016_pcbaTemp "UMC ECU: a016 pcba temp";
CM_ SG_ 1533 UMC_a017_wallPlugTemp "UMC ECU: a017 wall plug temp";
CM_ SG_ 1533 UMC_a017_SA_region "UMC ECU: a017 SA region";
CM_ SG_ 1533 UMC_a017_SA_current "UMC ECU: a017 SA current";
CM_ SG_ 1533 UMC_a018_vehConnTemp "UMC ECU: a018 veh conn temp";
CM_ SG_ 1533 UMC_a019_inputTerminalsTemp "UMC ECU: a019 input terminals temp";
CM_ SG_ 1533 UMC_a024_groundImpedance "UMC ECU: a024 ground impedance";
CM_ SG_ 1533 UMC_a040_groundImpedance "UMC ECU: a040 ground impedance";
CM_ BO_ 824 "UMC ECU message: alert matrix1";
CM_ SG_ 824 UMC_a001_gndMonIntrptLineSide "UMC ECU: a001 gnd mon intrpt line side";
CM_ SG_ 824 UMC_a002_GFCITripped "UMC ECU: a002 GFCI tripped";
CM_ SG_ 824 UMC_a003_GFCISelfTestFault "UMC ECU: a003 GFCI self test fault";
CM_ SG_ 824 UMC_a004_inputOverVoltage "UMC ECU: a004 input over voltage";
CM_ SG_ 824 UMC_a005_inputUnderVoltage "UMC ECU: a005 input under voltage";
CM_ SG_ 824 UMC_a006_contactorWelded "UMC ECU: a006 contactor welded";
CM_ SG_ 824 UMC_a007_pcbaOT "UMC ECU: a007 pcba OT";
CM_ SG_ 824 UMC_a008_wallPlugOT "UMC ECU: a008 wall plug OT";
CM_ SG_ 824 UMC_a009_vehConnOT "UMC ECU: a009 veh conn OT";
CM_ SG_ 824 UMC_a010_inputOT "UMC ECU: a010 input OT";
CM_ SG_ 824 UMC_a011_proxDisconnected "UMC ECU: a011 prox disconnected";
CM_ SG_ 824 UMC_a012_pilotFault "UMC ECU: a012 pilot fault";
CM_ SG_ 824 UMC_a013_SA_Temperature "UMC ECU: a013 SA temperature";
CM_ SG_ 824 UMC_a014_SA_Genealogy "UMC ECU: a014 SA genealogy";
CM_ SG_ 824 UMC_a015_SA_Connection "UMC ECU: a015 SA connection";
CM_ SG_ 824 UMC_a016_pcbaOTFoldback "UMC ECU: a016 pcba OT foldback";
CM_ SG_ 824 UMC_a017_wallPlugOTFoldback "UMC ECU: a017 wall plug OT foldback";
CM_ SG_ 824 UMC_a018_vehConnOTFoldback "UMC ECU: a018 veh conn OT foldback";
CM_ SG_ 824 UMC_a019_inputOTFoldback "UMC ECU: a019 input OT foldback";
CM_ SG_ 824 UMC_a020_applicationCRC "UMC ECU: a020 application CRC";
CM_ SG_ 824 UMC_a021_dataBus "UMC ECU: a021 data bus";
CM_ SG_ 824 UMC_a022_criticalRAM "UMC ECU: a022 critical RAM";
CM_ SG_ 824 UMC_a023_adcSelfTest "UMC ECU: a023 adc self test";
CM_ SG_ 824 UMC_a024_gndResistanceHigh "UMC ECU: a024 gnd resistance high";
CM_ SG_ 824 UMC_a025_cntrOpenExpectedClose "UMC ECU: a025 cntr open expected close";
CM_ SG_ 824 UMC_a026_vRefOutOfRange "UMC ECU: a026 v ref out of range";
CM_ SG_ 824 UMC_a027_watchdogExpired "UMC ECU: a027 watchdog expired";
CM_ SG_ 824 UMC_a028_processorBooted "UMC ECU: a028 processor booted";
CM_ SG_ 824 UMC_a029_acPowerLoss "UMC ECU: a029 ac power loss";
CM_ SG_ 824 UMC_a030_acLostPllLock "UMC ECU: a030 ac lost pll lock";
CM_ SG_ 824 UMC_a031_relayCoilVIrrational "UMC ECU: a031 relay coil v irrational";
CM_ SG_ 824 UMC_a032_chcVitalsRequestFailure "UMC ECU: a032 chc vitals request failure";
CM_ SG_ 824 UMC_a033_chcUpdateFault "UMC ECU: a033 chc update fault";
CM_ SG_ 824 UMC_a034_v2lSAUnsupported "UMC ECU: a034 v2l SA unsupported";
CM_ SG_ 824 UMC_a035_v2lHVACDetected "UMC ECU: a035 v2l HVAC detected";
CM_ SG_ 824 UMC_a037_GFCICalibration "UMC ECU: a037 GFCI calibration";
CM_ SG_ 824 UMC_a038_chcVitalsFault "UMC ECU: a038 chc vitals fault";
CM_ SG_ 824 UMC_a039_inputOverCurrent "UMC ECU: a039 input over current";
CM_ SG_ 824 UMC_a040_gndDisconnected "UMC ECU: a040 gnd disconnected";
CM_ BO_ 1285 "UMC ECU message: smart adapter info";
CM_ SG_ 1285 SA_infoIndex "UMC ECU: info index";
CM_ SG_ 1285 SA_genealogyVersion "UMC ECU: genealogy version";
CM_ SG_ 1285 SA_genealogyCrc "UMC ECU: genealogy crc";
CM_ SG_ 1285 SA_region "Reports the smart adapter region from Electrically Erasable Programmable Read-Only Memory (EEPROM).";
CM_ SG_ 1285 SA_OverTempThreshold "Reports the smart adapter overtemperature threshold from Electrically Erasable Programmable Read-Only Memory (EEPROM).";
CM_ SG_ 1285 SA_partNumInt "Reports the smart adapter part number integer representation.";
CM_ SG_ 1285 SA_partNumRev "Reports the smart adapter part number revision.";
CM_ SG_ 1285 SA_currentLimit "Reports the smart adapter current limit from Electrically Erasable Programmable Read-Only Memory (EEPROM).";
CM_ SG_ 1285 SA_l1Voltage "Reports the smart adapter nominal voltage request from Electrically Erasable Programmable Read-Only Memory (EEPROM).";
BA_DEF_ BO_ "GenMsgCycleTime" INT 0 3600000;
BA_DEF_ BO_ "GenMsgSendType" ENUM "Cyclic","NotUsed","NotUsed","NotUsed","NotUsed","NotUsed","NotUsed","IfActive","NoMsgSendType","NotUsed";
BA_DEF_ BO_ "VFrameFormat" ENUM "StandardCAN","ExtendedCAN","reserved","J1939PG","reserved","reserved","reserved","reserved","reserved","reserved","reserved","reserved","reserved","reserved","StandardCAN_FD","ExtendedCAN_FD";
BA_DEF_ BO_ "CANFD_BRS" ENUM "0","1";
BA_DEF_ SG_ "GenSigSNA" STRING;
BA_DEF_ SG_ "SystemSignalLongSymbol" STRING;
BA_DEF_ SG_ "Confidence" ENUM "validated","plausible","layout-only","contradicted";
BA_DEF_DEF_ "GenMsgCycleTime" 0;
BA_DEF_DEF_ "GenMsgSendType" "NoMsgSendType";
BA_DEF_DEF_ "VFrameFormat" "StandardCAN";
BA_DEF_DEF_ "CANFD_BRS" "1";
BA_DEF_DEF_ "GenSigSNA" "";
BA_DEF_DEF_ "SystemSignalLongSymbol" "";
BA_DEF_DEF_ "Confidence" "layout-only";
BA_ "GenMsgCycleTime" BO_ 139 1000;
BA_ "GenMsgSendType" BO_ 139 0;
BA_ "GenMsgCycleTime" BO_ 1173 1000;
BA_ "GenMsgSendType" BO_ 1173 0;
BA_ "GenMsgCycleTime" BO_ 1174 1000;
BA_ "GenMsgSendType" BO_ 1174 0;
BA_ "GenMsgCycleTime" BO_ 1175 1000;
BA_ "GenMsgSendType" BO_ 1175 0;
BA_ "GenMsgCycleTime" BO_ 627 500;
BA_ "GenMsgSendType" BO_ 627 0;
BA_ "GenMsgCycleTime" BO_ 947 500;
BA_ "GenMsgSendType" BO_ 947 0;
BA_ "GenMsgCycleTime" BO_ 628 500;
BA_ "GenMsgSendType" BO_ 628 0;
BA_ "GenMsgCycleTime" BO_ 853 1000;
BA_ "GenMsgSendType" BO_ 853 0;
BA_ "GenMsgCycleTime" BO_ 644 500;
BA_ "GenMsgSendType" BO_ 644 0;
BA_ "GenMsgCycleTime" BO_ 595 500;
BA_ "GenMsgSendType" BO_ 595 0;
BA_ "GenMsgCycleTime" BO_ 1569 500;
BA_ "GenMsgSendType" BO_ 1569 0;
BA_ "GenMsgCycleTime" BO_ 824 1000;
BA_ "GenMsgSendType" BO_ 824 0;
BA_ "GenMsgCycleTime" BO_ 1285 100;
BA_ "GenMsgSendType" BO_ 1285 0;
BA_ "Confidence" SG_ 139 UI_maxSpeedToReachDestination 0;
BA_ "GenSigSNA" SG_ 139 UI_maxSpeedToReachDestination "65535";
BA_ "Confidence" SG_ 139 UI_remainingWeightedRMSSpeed 1;
BA_ "GenSigSNA" SG_ 139 UI_remainingWeightedRMSSpeed "65535";
BA_ "Confidence" SG_ 139 UI_timeToDestination 0;
BA_ "GenSigSNA" SG_ 139 UI_timeToDestination "65535";
BA_ "Confidence" SG_ 1173 UI_predictedEnergy 0;
BA_ "GenSigSNA" SG_ 1173 UI_predictedEnergy "32768";
BA_ "Confidence" SG_ 1173 UI_predictedEnergyLearned 1;
BA_ "GenSigSNA" SG_ 1173 UI_predictedEnergyLearned "32768";
BA_ "Confidence" SG_ 1173 UI_hindsightEnergy 0;
BA_ "GenSigSNA" SG_ 1173 UI_hindsightEnergy "32768";
BA_ "Confidence" SG_ 1173 UI_hindsightEnergyLearned 1;
BA_ "GenSigSNA" SG_ 1173 UI_hindsightEnergyLearned "32768";
BA_ "Confidence" SG_ 1174 UI_longTermEnergyModelError 1;
BA_ "GenSigSNA" SG_ 1174 UI_longTermEnergyModelError "128";
BA_ "Confidence" SG_ 1174 UI_longTermRmsSpeedRatio 1;
BA_ "GenSigSNA" SG_ 1174 UI_longTermRmsSpeedRatio "255";
BA_ "Confidence" SG_ 1174 UI_gradeCorrectedEnergy 1;
BA_ "GenSigSNA" SG_ 1174 UI_gradeCorrectedEnergy "32768";
BA_ "Confidence" SG_ 1174 UI_gradeCorrectedEnergyLearned 1;
BA_ "GenSigSNA" SG_ 1174 UI_gradeCorrectedEnergyLearned "32768";
BA_ "Confidence" SG_ 1175 UI_battPreconditionOnNavTime 1;
BA_ "GenSigSNA" SG_ 1175 UI_battPreconditionOnNavTime "65535";
BA_ "Confidence" SG_ 1175 UI_maxBattPreconditionOnNavTime 1;
BA_ "GenSigSNA" SG_ 1175 UI_maxBattPreconditionOnNavTime "65535";
BA_ "Confidence" SG_ 1175 UI_tripPlanChargingTargetPercent 1;
BA_ "GenSigSNA" SG_ 1175 UI_tripPlanChargingTargetPercent "1023";
BA_ "Confidence" SG_ 1827 UI_ussSensorIdX 1;
BA_ "Confidence" SG_ 1829 UI_ussSensorIdY 1;
BA_ "Confidence" SG_ 627 UI_powerStateRequest 0;
BA_ "Confidence" SG_ 627 UI_childDoorLockOnRight 0;
BA_ "Confidence" SG_ 627 UI_frontFogSwitch 0;
BA_ "Confidence" SG_ 627 UI_summonActive 0;
BA_ "Confidence" SG_ 627 UI_frunkRequest 0;
BA_ "Confidence" SG_ 627 UI_wiperMode 0;
BA_ "GenSigSNA" SG_ 627 UI_wiperMode "0";
BA_ "Confidence" SG_ 627 UI_steeringBacklightEnabled 1;
BA_ "Confidence" SG_ 627 UI_steeringButtonMode 0;
BA_ "Confidence" SG_ 627 UI_walkUpUnlock 0;
BA_ "Confidence" SG_ 627 UI_walkAwayLock 0;
BA_ "Confidence" SG_ 627 UI_unlockOnPark 0;
BA_ "Confidence" SG_ 627 UI_globalUnlockOn 0;
BA_ "Confidence" SG_ 627 UI_childDoorLockOnLeft 0;
BA_ "Confidence" SG_ 627 UI_lockRequest 0;
BA_ "GenSigSNA" SG_ 627 UI_lockRequest "7";
BA_ "Confidence" SG_ 627 UI_alarmEnabled 0;
BA_ "Confidence" SG_ 627 UI_intrusionSensorOn 1;
BA_ "Confidence" SG_ 627 UI_stop12vSupport 0;
BA_ "Confidence" SG_ 627 UI_rearFogSwitch 0;
BA_ "Confidence" SG_ 627 UI_mirrorFoldRequest 0;
BA_ "GenSigSNA" SG_ 627 UI_mirrorFoldRequest "3";
BA_ "Confidence" SG_ 627 UI_mirrorHeatRequest 0;
BA_ "Confidence" SG_ 627 UI_remoteStartRequest 0;
BA_ "GenSigSNA" SG_ 627 UI_remoteStartRequest "4";
BA_ "Confidence" SG_ 627 UI_seeYouHomeLightingOn 0;
BA_ "Confidence" SG_ 627 UI_powerOff 0;
BA_ "Confidence" SG_ 627 UI_displayBrightnessLevel 0;
BA_ "GenSigSNA" SG_ 627 UI_displayBrightnessLevel "255";
BA_ "Confidence" SG_ 627 UI_ambientLightingEnabled 1;
BA_ "Confidence" SG_ 627 UI_autoHighBeamEnabled 0;
BA_ "Confidence" SG_ 627 UI_frontLeftSeatHeatReq 0;
BA_ "Confidence" SG_ 627 UI_frontRightSeatHeatReq 0;
BA_ "Confidence" SG_ 627 UI_rearLeftSeatHeatReq 0;
BA_ "Confidence" SG_ 627 UI_rearCenterSeatHeatReq 0;
BA_ "Confidence" SG_ 627 UI_rearRightSeatHeatReq 0;
BA_ "Confidence" SG_ 627 UI_autoFoldMirrorsOn 0;
BA_ "Confidence" SG_ 627 UI_mirrorDipOnReverse 0;
BA_ "Confidence" SG_ 627 UI_remoteClosureRequest 0;
BA_ "GenSigSNA" SG_ 627 UI_remoteClosureRequest "3";
BA_ "Confidence" SG_ 627 UI_wiperRequest 0;
BA_ "GenSigSNA" SG_ 627 UI_wiperRequest "0";
BA_ "Confidence" SG_ 627 UI_domeLightSwitch 0;
BA_ "Confidence" SG_ 627 UI_honkHorn 1;
BA_ "Confidence" SG_ 627 UI_driveStateRequest 1;
BA_ "Confidence" SG_ 627 UI_rearWindowLockout 1;
BA_ "Confidence" SG_ 947 UI_gloveboxRequest 0;
BA_ "Confidence" SG_ 947 UI_trunkRequest 0;
BA_ "Confidence" SG_ 947 UI_UMCUpdateInhibit 1;
BA_ "Confidence" SG_ 947 UI_WCUpdateInhibit 1;
BA_ "Confidence" SG_ 947 UI_soundHornOnLock 1;
BA_ "Confidence" SG_ 947 UI_locksPanelActive 1;
BA_ "Confidence" SG_ 947 UI_PINToDriveEnabled 0;
BA_ "Confidence" SG_ 947 UI_PINToDrivePassed 0;
BA_ "Confidence" SG_ 947 UI_disableMirrorAutoDim 0;
BA_ "Confidence" SG_ 947 UI_lightSwitch 0;
BA_ "GenSigSNA" SG_ 947 UI_lightSwitch "4";
BA_ "Confidence" SG_ 947 UI_readyToAddKey 0;
BA_ "Confidence" SG_ 947 UI_alarmTriggerRequest 0;
BA_ "Confidence" SG_ 947 UI_VCSECFeature1 1;
BA_ "Confidence" SG_ 947 UI_VCLEFTFeature1 1;
BA_ "Confidence" SG_ 947 UI_summonState 1;
BA_ "GenSigSNA" SG_ 947 UI_summonState "0";
BA_ "Confidence" SG_ 947 UI_displayOnForUser 0;
BA_ "Confidence" SG_ 947 UI_freeRollModeRequest 1;
BA_ "Confidence" SG_ 947 UI_BLEPushNotificationRequest 0;
BA_ "Confidence" SG_ 947 UI_pairKeyQRCodeDisplaying 1;
BA_ "Confidence" SG_ 947 UI_keepAutopilotAwake 0;
BA_ "Confidence" SG_ 947 UI_batteryPreconditioningRequest 0;
BA_ "Confidence" SG_ 947 UI_coastDownMode 1;
BA_ "Confidence" SG_ 947 UI_autopilotPowerStateRequest 0;
BA_ "Confidence" SG_ 947 UI_shorted12VCellTestMode 1;
BA_ "Confidence" SG_ 947 UI_autoRollWindowsOnLockEnable 0;
BA_ "Confidence" SG_ 947 UI_virtualPitchSensorOverrideOKF 1;
BA_ "SystemSignalLongSymbol" SG_ 947 UI_virtualPitchSensorOverrideOKF "UI_virtualPitchSensorOverrideOKForAim";
BA_ "Confidence" SG_ 947 UI_conditionalLoggingEnabledVCSE 1;
BA_ "SystemSignalLongSymbol" SG_ 947 UI_conditionalLoggingEnabledVCSE "UI_conditionalLoggingEnabledVCSEC";
BA_ "Confidence" SG_ 947 UI_WC3UpdateInhibit 1;
BA_ "Confidence" SG_ 947 UI_steeringWheelHeatReq 0;
BA_ "Confidence" SG_ 947 UI_disableHorn 0;
BA_ "Confidence" SG_ 947 UI_frontLeftSeatFanReq 0;
BA_ "Confidence" SG_ 947 UI_frontRightSeatAutoClimateReq 0;
BA_ "Confidence" SG_ 947 UI_frontRightSeatFanReq 0;
BA_ "Confidence" SG_ 947 UI_sleepFeature1 1;
BA_ "Confidence" SG_ 947 UI_dcr12VThreshold 1;
BA_ "Confidence" SG_ 947 UI_frontLeftSeatAutoClimateReq 0;
BA_ "Confidence" SG_ 947 UI_wiperHeaterReq 0;
BA_ "Confidence" SG_ 947 UI_tireSeason 1;
BA_ "Confidence" SG_ 947 UI_saveTireConfigReq 1;
BA_ "Confidence" SG_ 947 UI_silentAlarm 0;
BA_ "Confidence" SG_ 947 UI_sleepFeature2 1;
BA_ "Confidence" SG_ 628 UI_lightFlashRequest 0;
BA_ "Confidence" SG_ 628 UI_keylessDrivingEnabled 1;
BA_ "Confidence" SG_ 628 UI_phoneCallActive 0;
BA_ "Confidence" SG_ 628 UI_drivingSideVEH 1;
BA_ "Confidence" SG_ 628 UI_keyPairResponse 1;
BA_ "Confidence" SG_ 628 UI_lightShowClosuresEnabled 0;
BA_ "Confidence" SG_ 628 UI_steeringWheelHeatAutoReq 0;
BA_ "Confidence" SG_ 628 UI_steeringWheelHeatLevelReq 0;
BA_ "Confidence" SG_ 628 UI_headlightPulseRequest 0;
BA_ "Confidence" SG_ 628 UI_VCSECFeature2 1;
BA_ "Confidence" SG_ 628 UI_VCSECFeature3 1;
BA_ "Confidence" SG_ 628 UI_VCSECFeature4 1;
BA_ "Confidence" SG_ 628 UI_VCSECFeature5 1;
BA_ "Confidence" SG_ 628 UI_shortHornRequest 1;
BA_ "Confidence" SG_ 628 UI_packTempLoggingRequest 1;
BA_ "Confidence" SG_ 628 UI_UMC3UpdateInhibit 1;
BA_ "Confidence" SG_ 628 UI_handsFreeTrunk 1;
BA_ "Confidence" SG_ 628 UI_displayRedShiftActive 0;
BA_ "Confidence" SG_ 628 UI_handsFreeFrunk 1;
BA_ "Confidence" SG_ 628 UI_fasciaCameraWashRequest 0;
BA_ "Confidence" SG_ 628 UI_autoClosuresExcludeHome 1;
BA_ "Confidence" SG_ 628 UI_leftRearSeatAdjustmentRequest 0;
BA_ "Confidence" SG_ 628 UI_rightRearSeatAdjustmentReques 0;
BA_ "SystemSignalLongSymbol" SG_ 628 UI_rightRearSeatAdjustmentReques "UI_rightRearSeatAdjustmentRequest";
BA_ "Confidence" SG_ 628 UI_blindSpotIndicatorLightReques 0;
BA_ "SystemSignalLongSymbol" SG_ 628 UI_blindSpotIndicatorLightReques "UI_blindSpotIndicatorLightRequest";
BA_ "Confidence" SG_ 628 UI_etcBluetoothControl 1;
BA_ "Confidence" SG_ 628 UI_keepOnAccessoryPortsReq 0;
BA_ "Confidence" SG_ 628 UI_fasciaCameraShown 0;
BA_ "Confidence" SG_ 628 UI_rearSeatChildLock 0;
BA_ "Confidence" SG_ 628 UI_windowPercentageRequest 0;
BA_ "Confidence" SG_ 628 UI_windowRequestedFL 0;
BA_ "Confidence" SG_ 628 UI_windowRequestedFR 0;
BA_ "Confidence" SG_ 628 UI_windowRequestedRL 0;
BA_ "Confidence" SG_ 628 UI_windowRequestedRR 0;
BA_ "Confidence" SG_ 628 UI_windowRequest 0;
BA_ "Confidence" SG_ 628 UI_closeTrunkRequest 0;
BA_ "Confidence" SG_ 628 UI_childPresenceDetectionDisable 0;
BA_ "SystemSignalLongSymbol" SG_ 628 UI_childPresenceDetectionDisable "UI_childPresenceDetectionDisableRequest";
BA_ "Confidence" SG_ 628 UI_derivedLoadshedFeature 0;
BA_ "Confidence" SG_ 628 UI_rearSeatFoldConfirmed 1;
BA_ "Confidence" SG_ 628 UI_leftRearSeatRequestFromRearDi 1;
BA_ "SystemSignalLongSymbol" SG_ 628 UI_leftRearSeatRequestFromRearDi "UI_leftRearSeatRequestFromRearDisplay";
BA_ "Confidence" SG_ 628 UI_selfParkStandingBy 0;
BA_ "Confidence" SG_ 628 UI_rightRearSeatRequestFromRearD 1;
BA_ "SystemSignalLongSymbol" SG_ 628 UI_rightRearSeatRequestFromRearD "UI_rightRearSeatRequestFromRearDisplay";
BA_ "Confidence" SG_ 853 UI_coolantFlowRequest 0;
BA_ "Confidence" SG_ 853 UI_inletActiveCoolTarget 0;
BA_ "Confidence" SG_ 853 UI_disableHVPTThermalLoads 0;
BA_ "Confidence" SG_ 853 UI_enableCompLiquidPumpOut 1;
BA_ "Confidence" SG_ 853 UI_enableCOP1HighSHOperation 1;
BA_ "Confidence" SG_ 853 UI_enableIncreasedEvapRampRate 1;
BA_ "Confidence" SG_ 853 UI_enableCOP1BatteryHeating 1;
BA_ "Confidence" SG_ 853 UI_enableCOP1CabinHeatingBattery 1;
BA_ "SystemSignalLongSymbol" SG_ 853 UI_enableCOP1CabinHeatingBattery "UI_enableCOP1CabinHeatingBatteryHeating";
BA_ "Confidence" SG_ 853 UI_enableLouverAutoDetection 1;
BA_ "Confidence" SG_ 853 UI_enableUserFacingLowFlowDelive 1;
BA_ "SystemSignalLongSymbol" SG_ 853 UI_enableUserFacingLowFlowDelive "UI_enableUserFacingLowFlowDeliveryAlert";
BA_ "Confidence" SG_ 853 UI_disableHvacCameraOnlyDefog 1;
BA_ "Confidence" SG_ 853 UI_enableEXVFastCalibration 1;
BA_ "Confidence" SG_ 853 UI_geofencedLiftgateHeight 1;
BA_ "GenSigSNA" SG_ 853 UI_geofencedLiftgateHeight "255";
BA_ "Confidence" SG_ 853 UI_enableConservativeBatteryHeat 1;
BA_ "SystemSignalLongSymbol" SG_ 853 UI_enableConservativeBatteryHeat "UI_enableConservativeBatteryHeating";
BA_ "Confidence" SG_ 853 UI_enableDefaultApTempTarget 1;
BA_ "Confidence" SG_ 644 UI_factoryMode 1;
BA_ "Confidence" SG_ 644 UI_transportMode 0;
BA_ "Confidence" SG_ 644 UI_showroomMode 0;
BA_ "Confidence" SG_ 644 UI_serviceMode 0;
BA_ "Confidence" SG_ 644 UI_isDelivered 1;
BA_ "Confidence" SG_ 644 UI_hasEverBeenDelivered 1;
BA_ "Confidence" SG_ 644 UI_homelinkV2Command0 1;
BA_ "Confidence" SG_ 644 UI_homelinkV2Command1 1;
BA_ "Confidence" SG_ 644 UI_homelinkV2Command2 1;
BA_ "Confidence" SG_ 644 UI_carWashMode 0;
BA_ "Confidence" SG_ 644 UI_valetMode 1;
BA_ "Confidence" SG_ 644 UI_gameMode 0;
BA_ "Confidence" SG_ 644 UI_diagnosticsAllowed 1;
BA_ "Confidence" SG_ 644 UI_serviceModePlus 0;
BA_ "Confidence" SG_ 644 UI_premiumAmpPowerOff 0;
BA_ "Confidence" SG_ 644 UI_signedCmdHardLocked 1;
BA_ "Confidence" SG_ 644 UI_signedCmdServiceMode 1;
BA_ "Confidence" SG_ 644 UI_closureEasterEggStatus 1;
BA_ "Confidence" SG_ 644 UI_lightShowType 0;
BA_ "Confidence" SG_ 644 UI_sohTestRequest 1;
BA_ "Confidence" SG_ 644 UI_vehicleModesCounter 1;
BA_ "Confidence" SG_ 644 UI_vehicleModesChecksum 0;
BA_ "Confidence" SG_ 595 UI_ventPanelControlRequestIndex 1;
BA_ "Confidence" SG_ 595 UI_ventPanelLeftPositionX 0;
BA_ "Confidence" SG_ 595 UI_ventPanelLeftPositionY 0;
BA_ "Confidence" SG_ 595 UI_ventPanelLeftLateralSplit 0;
BA_ "Confidence" SG_ 595 UI_ventPanelRightPositionX 0;
BA_ "Confidence" SG_ 595 UI_ventPanelRightPositionY 0;
BA_ "Confidence" SG_ 595 UI_ventPanelRightLateralSplit 0;
BA_ "Confidence" SG_ 595 UI_ventPanelLeftLateralMode 0;
BA_ "Confidence" SG_ 595 UI_ventPanelRightLateralMode 0;
BA_ "Confidence" SG_ 595 UI_hvacReqActiveVents 0;
BA_ "Confidence" SG_ 595 UI_vent2RLeftPositionX 0;
BA_ "Confidence" SG_ 595 UI_vent2RLeftPositionY 0;
BA_ "Confidence" SG_ 595 UI_vent2RRightPositionX 0;
BA_ "Confidence" SG_ 595 UI_vent2RRightPositionY 0;
BA_ "Confidence" SG_ 1569 UI_weatherSvcTimeSinceLast 1;
BA_ "GenSigSNA" SG_ 1569 UI_weatherSvcTimeSinceLast "2047";
BA_ "Confidence" SG_ 1569 UI_weatherSvcTemperature 1;
BA_ "GenSigSNA" SG_ 1569 UI_weatherSvcTemperature "127";
BA_ "Confidence" SG_ 1569 UI_weatherSvcHumidity 1;
BA_ "GenSigSNA" SG_ 1569 UI_weatherSvcHumidity "255";
BA_ "Confidence" SG_ 1569 UI_weatherSvcDewPoint 1;
BA_ "GenSigSNA" SG_ 1569 UI_weatherSvcDewPoint "255";
BA_ "Confidence" SG_ 1569 UI_weatherSvcCloudCover 1;
BA_ "GenSigSNA" SG_ 1569 UI_weatherSvcCloudCover "255";
BA_ "Confidence" SG_ 1533 UMC_alertID 1;
BA_ "Confidence" SG_ 1533 UMC_alertType 1;
BA_ "Confidence" SG_ 1533 UMC_a001_groundImpedance 1;
BA_ "Confidence" SG_ 1533 UMC_a002_ccidRmsCurrent 1;
BA_ "Confidence" SG_ 1533 UMC_a002_ccidRmsCurrentAvg 1;
BA_ "Confidence" SG_ 1533 UMC_a002_ccidFaultReason 1;
BA_ "GenSigSNA" SG_ 1533 UMC_a002_ccidFaultReason "0";
BA_ "Confidence" SG_ 1533 UMC_a003_faultType 1;
BA_ "Confidence" SG_ 1533 UMC_a003_ccidSelfTestDuty 1;
BA_ "Confidence" SG_ 1533 UMC_a003_ccidSelfTestCurrent 1;
BA_ "Confidence" SG_ 1533 UMC_a004_lineVoltage 1;
BA_ "Confidence" SG_ 1533 UMC_a004_inputVoltage 1;
BA_ "Confidence" SG_ 1533 UMC_a004_inputNeutralVoltage 1;
BA_ "Confidence" SG_ 1533 UMC_a005_lineVoltage 1;
BA_ "Confidence" SG_ 1533 UMC_a005_inputVoltage 1;
BA_ "Confidence" SG_ 1533 UMC_a005_inputNeutralVoltage 1;
BA_ "Confidence" SG_ 1533 UMC_a006_outputVoltage 1;
BA_ "Confidence" SG_ 1533 UMC_a006_faultType 1;
BA_ "Confidence" SG_ 1533 UMC_a006_umcReceptacleVoltage 1;
BA_ "Confidence" SG_ 1533 UMC_a006_handleVoltage 1;
BA_ "Confidence" SG_ 1533 UMC_a007_pcbaTemp 1;
BA_ "Confidence" SG_ 1533 UMC_a008_wallPlugTemp 1;
BA_ "Confidence" SG_ 1533 UMC_a008_SA_current 1;
BA_ "Confidence" SG_ 1533 UMC_a009_vehConnTemp 1;
BA_ "Confidence" SG_ 1533 UMC_a010_inputTerminalsTemp 1;
BA_ "Confidence" SG_ 1533 UMC_a012_pilotHigh 1;
BA_ "Confidence" SG_ 1533 UMC_a012_pilotLow 1;
BA_ "Confidence" SG_ 1533 UMC_a013_SA_current 1;
BA_ "Confidence" SG_ 1533 UMC_a015_SA_current 1;
BA_ "Confidence" SG_ 1533 UMC_a016_pcbaTemp 1;
BA_ "Confidence" SG_ 1533 UMC_a017_wallPlugTemp 1;
BA_ "Confidence" SG_ 1533 UMC_a017_SA_current 1;
BA_ "Confidence" SG_ 1533 UMC_a018_vehConnTemp 1;
BA_ "Confidence" SG_ 1533 UMC_a019_inputTerminalsTemp 1;
BA_ "Confidence" SG_ 1533 UMC_a024_groundImpedance 1;
BA_ "Confidence" SG_ 1533 UMC_a040_groundImpedance 1;
BA_ "Confidence" SG_ 1285 SA_infoIndex 1;
BA_ "Confidence" SG_ 1285 SA_genealogyVersion 0;
BA_ "Confidence" SG_ 1285 SA_genealogyCrc 0;
BA_ "Confidence" SG_ 1285 SA_region 0;
BA_ "Confidence" SG_ 1285 SA_OverTempThreshold 0;
BA_ "Confidence" SG_ 1285 SA_partNumInt 0;
BA_ "Confidence" SG_ 1285 SA_partNumRev 0;
BA_ "Confidence" SG_ 1285 SA_currentLimit 0;
BA_ "Confidence" SG_ 1285 SA_l1Voltage 0;
VAL_ 139 UI_maxSpeedToReachDestination 65535 "SNA" 65534 "UNREACHABLE" 65533 "MAXVAL" ;
VAL_ 139 UI_remainingWeightedRMSSpeed 65535 "SNA" 65534 "MAXVAL" ;
VAL_ 139 UI_timeToDestination 65535 "SNA" 65534 "MAXVAL" ;
VAL_ 1173 UI_predictedEnergy -32767 "TRIP_TOO_LONG" -32768 "SNA" ;
VAL_ 1173 UI_predictedEnergyLearned -32767 "TRIP_TOO_LONG" -32768 "SNA" ;
VAL_ 1173 UI_hindsightEnergy -32767 "TRIP_TOO_LONG" -32768 "SNA" ;
VAL_ 1173 UI_hindsightEnergyLearned -32767 "TRIP_TOO_LONG" -32768 "SNA" ;
VAL_ 1174 UI_longTermEnergyModelError 127 "MAXVAL" -128 "SNA" ;
VAL_ 1174 UI_longTermRmsSpeedRatio 255 "SNA" 254 "MAXVAL" ;
VAL_ 1174 UI_gradeCorrectedEnergy -32767 "TRIP_TOO_LONG" -32768 "SNA" ;
VAL_ 1174 UI_gradeCorrectedEnergyLearned -32767 "TRIP_TOO_LONG" -32768 "SNA" ;
VAL_ 1175 UI_battPreconditionOnNavTime 65535 "SNA" 65534 "MAXVAL" ;
VAL_ 1175 UI_maxBattPreconditionOnNavTime 65535 "SNA" 65534 "MAXVAL" ;
VAL_ 1175 UI_tripPlanChargingTargetPercent 1023 "SNA" ;
VAL_ 1827 UI_ussSensorIdX 5 "FRONT_SIDE" 4 "FRONT_CORNER" 3 "FRONT_INNER" 2 "REAR_SIDE" 1 "REAR_CORNER" 0 "REAR_INNER" ;
VAL_ 1829 UI_ussSensorIdY 5 "FRONT_SIDE" 4 "FRONT_CORNER" 3 "FRONT_INNER" 2 "REAR_SIDE" 1 "REAR_CORNER" 0 "REAR_INNER" ;
VAL_ 627 UI_powerStateRequest 3 "DRIVE_SUMMON" 2 "ACCESSORY_PLUS" 1 "ACCESSORY" 0 "IDLE" ;
VAL_ 627 UI_wiperMode 3 "WIPER_MODE_PARK" 2 "WIPER_MODE_NORMAL" 1 "WIPER_MODE_SERVICE" 0 "WIPER_MODE_SNA" ;
VAL_ 627 UI_steeringBacklightEnabled 1 "ENABLED" 0 "DISABLED" ;
VAL_ 627 UI_steeringButtonMode 7 "STEERING_BUTTON_MODE_SEATS" 6 "STEERING_BUTTON_MODE_WIPERS" 5 "STEERING_BUTTON_MODE_HEADLIGHT_RIGHT" 4 "STEERING_BUTTON_MODE_HEADLIGHT_LEFT" 3 "STEERING_BUTTON_MODE_MIRROR_RIGHT" 2 "STEERING_BUTTON_MODE_MIRROR_LEFT" 1 "STEERING_BUTTON_MODE_STEERING_COLUMN_ADJ" 0 "STEERING_BUTTON_MODE_OFF" ;
VAL_ 627 UI_lockRequest 7 "UI_LOCK_REQUEST_SNA" 4 "UI_LOCK_REQUEST_REMOTE_LOCK" 3 "UI_LOCK_REQUEST_REMOTE_UNLOCK" 2 "UI_LOCK_REQUEST_UNLOCK" 1 "UI_LOCK_REQUEST_LOCK" 0 "UI_LOCK_REQUEST_IDLE" ;
VAL_ 627 UI_mirrorFoldRequest 3 "MIRROR_FOLD_REQUEST_SNA" 2 "MIRROR_FOLD_REQUEST_PRESENT" 1 "MIRROR_FOLD_REQUEST_RETRACT" 0 "MIRROR_FOLD_REQUEST_IDLE" ;
VAL_ 627 UI_remoteStartRequest 4 "UI_REMOTE_START_REQUEST_SNA" 1 "UI_REMOTE_START_REQUEST_START" 0 "UI_REMOTE_START_REQUEST_IDLE" ;
VAL_ 627 UI_displayBrightnessLevel 255 "SNA" ;
VAL_ 627 UI_frontLeftSeatHeatReq 3 "HEATER_REQUEST_LEVEL3" 2 "HEATER_REQUEST_LEVEL2" 1 "HEATER_REQUEST_LEVEL1" 0 "HEATER_REQUEST_OFF" ;
VAL_ 627 UI_frontRightSeatHeatReq 3 "HEATER_REQUEST_LEVEL3" 2 "HEATER_REQUEST_LEVEL2" 1 "HEATER_REQUEST_LEVEL1" 0 "HEATER_REQUEST_OFF" ;
VAL_ 627 UI_rearLeftSeatHeatReq 3 "HEATER_REQUEST_LEVEL3" 2 "HEATER_REQUEST_LEVEL2" 1 "HEATER_REQUEST_LEVEL1" 0 "HEATER_REQUEST_OFF" ;
VAL_ 627 UI_rearCenterSeatHeatReq 3 "HEATER_REQUEST_LEVEL3" 2 "HEATER_REQUEST_LEVEL2" 1 "HEATER_REQUEST_LEVEL1" 0 "HEATER_REQUEST_OFF" ;
VAL_ 627 UI_rearRightSeatHeatReq 3 "HEATER_REQUEST_LEVEL3" 2 "HEATER_REQUEST_LEVEL2" 1 "HEATER_REQUEST_LEVEL1" 0 "HEATER_REQUEST_OFF" ;
VAL_ 627 UI_remoteClosureRequest 3 "UI_REMOTE_CLOSURE_REQUEST_SNA" 2 "UI_REMOTE_CLOSURE_REQUEST_FRONT_TRUNK_MOVE" 1 "UI_REMOTE_CLOSURE_REQUEST_REAR_TRUNK_MOVE" 0 "UI_REMOTE_CLOSURE_REQUEST_IDLE" ;
VAL_ 627 UI_wiperRequest 6 "WIPER_REQUEST_FAST_CONTINUOUS" 5 "WIPER_REQUEST_SLOW_CONTINUOUS" 4 "WIPER_REQUEST_FAST_INTERMITTENT" 3 "WIPER_REQUEST_SLOW_INTERMITTENT" 2 "WIPER_REQUEST_AUTO" 1 "WIPER_REQUEST_OFF" 0 "WIPER_REQUEST_SNA" ;
VAL_ 627 UI_domeLightSwitch 2 "DOME_LIGHT_SWITCH_AUTO" 1 "DOME_LIGHT_SWITCH_ON" 0 "DOME_LIGHT_SWITCH_OFF" ;
VAL_ 627 UI_driveStateRequest 1 "START" 0 "IDLE" ;
VAL_ 947 UI_lightSwitch 4 "LIGHT_SWITCH_SNA" 3 "LIGHT_SWITCH_OFF" 2 "LIGHT_SWITCH_PARKING" 1 "LIGHT_SWITCH_ON" 0 "LIGHT_SWITCH_AUTO" ;
VAL_ 947 UI_summonState 3 "ACTIVE" 2 "PRE_PRIMED" 1 "IDLE" 0 "SNA" ;
VAL_ 947 UI_autopilotPowerStateRequest 2 "AUTOPILOT_SUSPEND" 1 "AUTOPILOT_SENTRY" 0 "AUTOPILOT_NOMINAL" ;
VAL_ 947 UI_shorted12VCellTestMode 2 "ACTIVE" 1 "SHADOW" 0 "DISABLED" ;
VAL_ 947 UI_frontLeftSeatFanReq 3 "FAN_REQUEST_LEVEL3" 2 "FAN_REQUEST_LEVEL2" 1 "FAN_REQUEST_LEVEL1" 0 "FAN_REQUEST_OFF" ;
VAL_ 947 UI_frontRightSeatFanReq 3 "FAN_REQUEST_LEVEL3" 2 "FAN_REQUEST_LEVEL2" 1 "FAN_REQUEST_LEVEL1" 0 "FAN_REQUEST_OFF" ;
VAL_ 947 UI_dcr12VThreshold 12 "15_MILLIOHMS" 11 "16_MILLIOHMS" 10 "17_MILLIOHMS" 9 "18_MILLIOHMS" 8 "19_MILLIOHMS" 7 "20_MILLIOHMS" 6 "22_MILLIOHMS" 5 "24_MILLIOHMS" 4 "27_MILLIOHMS" 3 "30_MILLIOHMS" 2 "35_MILLIOHMS" 1 "40_MILLIOHMS" 0 "OFF" ;
VAL_ 947 UI_tireSeason 1 "WINTER" 0 "NON_WINTER" ;
VAL_ 947 UI_saveTireConfigReq 1 "TRUE" 0 "FALSE" ;
VAL_ 628 UI_lightFlashRequest 3 "LIGHT_FLASH_SENTRY" 2 "LIGHT_FLASH_MOBILE_APP" 1 "LIGHT_FLASH_HOMELINK" 0 "LIGHT_FLASH_INACTIVE" ;
VAL_ 628 UI_drivingSideVEH 2 "UNKNOWN" 1 "RIGHT" 0 "LEFT" ;
VAL_ 628 UI_keyPairResponse 2 "DENIED" 1 "CONFIRMED" 0 "NONE" ;
VAL_ 628 UI_steeringWheelHeatLevelReq 3 "STEERING_WHEEL_HEAT_LEVEL3" 2 "STEERING_WHEEL_HEAT_LEVEL2" 1 "STEERING_WHEEL_HEAT_LEVEL1" 0 "STEERING_WHEEL_HEAT_OFF" ;
VAL_ 628 UI_packTempLoggingRequest 1 "TRUE" 0 "FALSE" ;
VAL_ 628 UI_leftRearSeatAdjustmentRequest 6 "UI_ADJUSTABLE_FOLD_FLAT_REQUEST_STOP" 5 "UI_ADJUSTABLE_FOLD_FLAT_REQUEST_TOGGLE_FOLD" 4 "UI_ADJUSTABLE_FOLD_FLAT_REQUEST_REARWARD_FAST" 3 "UI_ADJUSTABLE_FOLD_FLAT_REQUEST_REARWARD_COMFORT" 2 "UI_ADJUSTABLE_FOLD_FLAT_REQUEST_FORWARD_FAST" 1 "UI_ADJUSTABLE_FOLD_FLAT_REQUEST_FORWARD_COMFORT" 0 "UI_ADJUSTABLE_FOLD_FLAT_REQUEST_NONE" ;
VAL_ 628 UI_rightRearSeatAdjustmentReques 6 "UI_ADJUSTABLE_FOLD_FLAT_REQUEST_STOP" 5 "UI_ADJUSTABLE_FOLD_FLAT_REQUEST_TOGGLE_FOLD" 4 "UI_ADJUSTABLE_FOLD_FLAT_REQUEST_REARWARD_FAST" 3 "UI_ADJUSTABLE_FOLD_FLAT_REQUEST_REARWARD_COMFORT" 2 "UI_ADJUSTABLE_FOLD_FLAT_REQUEST_FORWARD_FAST" 1 "UI_ADJUSTABLE_FOLD_FLAT_REQUEST_FORWARD_COMFORT" 0 "UI_ADJUSTABLE_FOLD_FLAT_REQUEST_NONE" ;
VAL_ 628 UI_etcBluetoothControl 3 "RESERVED" 2 "ON" 1 "OFF" 0 "INACTIVE" ;
VAL_ 628 UI_rearSeatChildLock 3 "UI_ADJUSTABLE_FOLD_FLAT_CHILD_LOCK_BOTH" 2 "UI_ADJUSTABLE_FOLD_FLAT_CHILD_LOCK_RIGHT" 1 "UI_ADJUSTABLE_FOLD_FLAT_CHILD_LOCK_LEFT" 0 "UI_ADJUSTABLE_FOLD_FLAT_CHILD_LOCK_NONE" ;
VAL_ 628 UI_windowRequest 6 "WINDOW_REQUEST_GOTO_RELATIVE_PERCENT" 5 "WINDOW_REQUEST_GOTO_CLOSED_CARWASH" 4 "WINDOW_REQUEST_GOTO_OPEN" 3 "WINDOW_REQUEST_GOTO_CLOSED" 2 "WINDOW_REQUEST_GOTO_VENT" 1 "WINDOW_REQUEST_GOTO_PERCENT" 0 "WINDOW_REQUEST_IDLE" ;
VAL_ 853 UI_geofencedLiftgateHeight 255 "INVALID_SNA" 1 "USE_DEFAULT" 0 "PENDING_SAVE" ;
VAL_ 644 UI_factoryMode 1 "ENABLED" 0 "DISABLED" ;
VAL_ 644 UI_transportMode 1 "TRANSPORT_MODE_ENABLED" 0 "TRANSPORT_MODE_DISABLED" ;
VAL_ 644 UI_showroomMode 1 "SHOWROOM_MODE_ENABLED" 0 "SHOWROOM_MODE_DISABLED" ;
VAL_ 644 UI_serviceMode 1 "SERVICE_MODE_ENABLED" 0 "SERVICE_MODE_DISABLED" ;
VAL_ 644 UI_diagnosticsAllowed 1 "ALLOWED" 0 "NOT_ALLOWED" ;
VAL_ 644 UI_serviceModePlus 1 "SERVICE_MODE_PLUS_ENABLED" 0 "SERVICE_MODE_PLUS_DISABLED" ;
VAL_ 644 UI_signedCmdHardLocked 1 "ENABLED" 0 "DISABLED" ;
VAL_ 644 UI_signedCmdServiceMode 1 "ENABLED" 0 "DISABLED" ;
VAL_ 644 UI_closureEasterEggStatus 3 "PLAYING" 2 "PRIMED" 1 "PRIMED_REMOTE" 0 "IDLE" ;
VAL_ 644 UI_lightShowType 5 "LIGHT_SHOW_TYPE_STANDARD_CNY24" 4 "LIGHT_SHOW_TYPE_STANDARD_THE_ARRIVAL" 3 "LIGHT_SHOW_TYPE_STANDARD_CNY23" 2 "LIGHT_SHOW_TYPE_STANDARD_AULD_LANG_SYNE" 1 "LIGHT_SHOW_TYPE_STANDARD_CAROL_OF_THE_BELLS" 0 "LIGHT_SHOW_TYPE_CUSTOM_USB" ;
VAL_ 595 UI_ventPanelControlRequestIndex 1 "1" 0 "0" ;
VAL_ 595 UI_ventPanelLeftLateralMode 2 "SWING" 1 "SPLIT" 0 "SINGLE" ;
VAL_ 595 UI_ventPanelRightLateralMode 2 "SWING" 1 "SPLIT" 0 "SINGLE" ;
VAL_ 595 UI_hvacReqActiveVents 3 "OFF" 2 "RIGHT" 1 "LEFT" 0 "BOTH" ;
VAL_ 1569 UI_weatherSvcTimeSinceLast 2047 "SNA" ;
VAL_ 1569 UI_weatherSvcTemperature 127 "SNA" 120 "MAX" -120 "MIN" ;
VAL_ 1569 UI_weatherSvcHumidity 255 "SNA" ;
VAL_ 1569 UI_weatherSvcDewPoint 255 "SNA" ;
VAL_ 1569 UI_weatherSvcCloudCover 255 "SNA" ;
VAL_ 1533 UMC_alertID 40 "a040_gndDisconnected" 39 "a039_inputOverCurrent" 38 "a038_chcVitalsFault" 37 "a037_GFCICalibration" 35 "a035_v2lHVACDetected" 34 "a034_v2lSAUnsupported" 33 "a033_chcUpdateFault" 32 "a032_chcVitalsRequestFailure" 31 "a031_relayCoilVIrrational" 30 "a030_acLostPllLock" 29 "a029_acPowerLoss" 28 "a028_processorBooted" 27 "a027_watchdogExpired" 26 "a026_vRefOutOfRange" 25 "a025_cntrOpenExpectedClose" 24 "a024_gndResistanceHigh" 23 "a023_adcSelfTest" 22 "a022_criticalRAM" 21 "a021_dataBus" 20 "a020_applicationCRC" 19 "a019_inputOTFoldback" 18 "a018_vehConnOTFoldback" 17 "a017_wallPlugOTFoldback" 16 "a016_pcbaOTFoldback" 15 "a015_SA_Connection" 14 "a014_SA_Genealogy" 13 "a013_SA_Temperature" 12 "a012_pilotFault" 11 "a011_proxDisconnected" 10 "a010_inputOT" 9 "a009_vehConnOT" 8 "a008_wallPlugOT" 7 "a007_pcbaOT" 6 "a006_contactorWelded" 5 "a005_inputUnderVoltage" 4 "a004_inputOverVoltage" 3 "a003_GFCISelfTestFault" 2 "a002_GFCITripped" 1 "a001_gndMonIntrptLineSide" 0 "ALERT_DO_NOT_USE_ZERO" ;
VAL_ 1533 UMC_alertType 1 "SET" 0 "CLEARED" ;
VAL_ 1533 UMC_a002_ccidFaultReason 4 "DC_PEAK" 3 "DC_LPF" 2 "AC_PEAK" 1 "AC_LPF" 0 "SNA" ;
VAL_ 1533 UMC_a003_faultType 1 "SELFTEST" 0 "POWERON" ;
VAL_ 1533 UMC_a006_faultType 1 "OPENED" 0 "WELDED" ;
VAL_ 1533 UMC_a018_vehConnTemp 215 "SHORTED" 214 "OPENED" ;
VAL_ 1533 UMC_a019_inputTerminalsTemp 215 "SHORTED" 214 "OPENED" ;
VAL_ 1285 SA_infoIndex 32 "Mux32" 31 "Mux31" 30 "Mux30" 29 "Mux29" 27 "Mux27" 26 "Mux26" 25 "Mux25" 11 "Mux11" 0 "Mux0" ;
VAL_ 1285 SA_region 6 "SA_REGION_INDIA" 5 "SA_REGION_SOUTH_KOREA" 4 "SA_REGION_AUSTRALIA" 3 "SA_REGION_JAPAN" 2 "SA_REGION_CHINA" 1 "SA_REGION_EU" 0 "SA_REGION_NA" ;
